VERSION "created by canmatrix"

NS_ :

BS_:

BU_: Pack01BMSLeader ExternalECU Pack02BMS Pack03BMS Pack04BMS Pack05BMS Pack06BMS Pack07BMS Pack08BMS Pack09BMS Pack10BMS Pack11BMS Pack12BMS Pack13BMS Pack14BMS Pack15BMS Pack16BMS

BO_ 2566834889 DM1: 550 Pack01BMSLeader

BO_ 2350631173 HVESSC1: 8 ExternalECU
 SG_ HVESS_High_Voltage_Bus_Connect_C : 0|2@1+ (1,0) [0|3] "" Pack01BMSLeader
 SG_ HVESS_Charging_Mode : 10|2@1+ (1,0) [0|3] "" Pack01BMSLeader

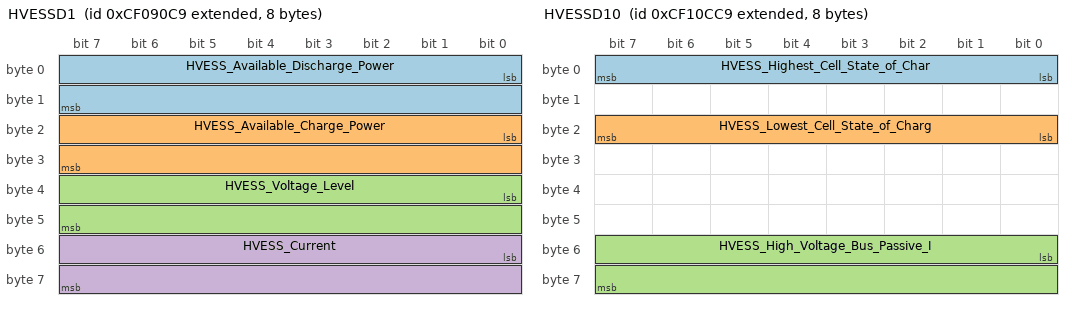
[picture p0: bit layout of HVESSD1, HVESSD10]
BO_ 2364575945 HVESSD1: 8 Pack01BMSLeader
 SG_ HVESS_Available_Discharge_Power : 0|16@1+ (0.05,0) [0|3276.75] "kW" Vector__XXX
 SG_ HVESS_Available_Charge_Power : 16|16@1+ (0.05,0) [0|3276.75] "kW" Vector__XXX
 SG_ HVESS_Voltage_Level : 32|16@1+ (0.05,0) [0|3276.75] "V" Vector__XXX
 SG_ HVESS_Current : 48|16@1+ (0.05,-1600) [-1600|1676.75] "A" Vector__XXX

BO_ 2364607689 HVESSD10: 8 Pack01BMSLeader
 SG_ HVESS_Highest_Cell_State_of_Char : 0|8@1+ (1,0) [0|255] "" Vector__XXX
 SG_ HVESS_Lowest_Cell_State_of_Charg : 16|8@1+ (1,0) [0|255] "" Vector__XXX
 SG_ HVESS_High_Voltage_Bus_Passive_I : 48|16@1+ (0.1,0) [0|6553.5] "ohm per V" Vector__XXX

BO_ 2365203657 HVESSD12: 8 Pack01BMSLeader
 SG_ HVESS_Estimated_Charge_Time_Rema : 24|16@1+ (0.1,0) [0|6553.5] "min" Vector__XXX

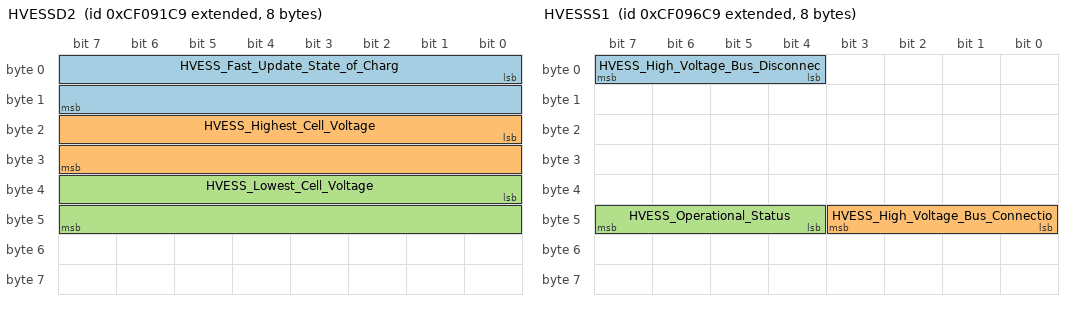
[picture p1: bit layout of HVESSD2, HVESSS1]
BO_ 2364576201 HVESSD2: 8 Pack01BMSLeader
 SG_ HVESS_Fast_Update_State_of_Charg : 0|16@1+ (0.0015625,0) [0|102.3984375] "%" Vector__XXX
 SG_ HVESS_Highest_Cell_Voltage : 16|16@1+ (0.001,0) [0|65.535] "V" Vector__XXX
 SG_ HVESS_Lowest_Cell_Voltage : 32|16@1+ (0.001,0) [0|65.535] "V" Vector__XXX

BO_ 2364576457 HVESSD3: 8 Pack01BMSLeader
 SG_ HVESS_Highest_Cell_Temperature : 0|16@1+ (0.03125,-273) [-273|1774.96875] "deg C" Vector__XXX
 SG_ HVESS_Lowest_Cell_Temperature : 16|16@1+ (0.03125,-273) [-273|1774.96875] "deg C" Vector__XXX

BO_ 2364576713 HVESSD4: 8 Pack01BMSLeader
 SG_ HVESS_Discharge_Capacity : 0|16@1+ (0.01,0) [0|655.35] "Ah" Vector__XXX
 SG_ HVESS_Charge_Capacity : 16|16@1+ (0.01,0) [0|655.35] "Ah" Vector__XXX

BO_ 2364576969 HVESSD5: 8 Pack01BMSLeader
 SG_ HVESS_Minimum_Cell_State_of_Char : 32|16@1+ (0.0015625,0) [0|102.3984375] "%" Vector__XXX
 SG_ HVESS_Maximum_Cell_State_of_Char : 48|16@1+ (0.0015625,0) [0|102.3984375] "%" Vector__XXX

BO_ 2364577225 HVESSD6: 8 Pack01BMSLeader
 SG_ HVESS_Bus_Voltage : 0|16@1+ (0.05,0) [0|3276.75] "V" Vector__XXX

BO_ 2364607177 HVESSD8: 8 Pack01BMSLeader
 SG_ HVESS_Highest_Cell_Voltage_Pack_ : 0|8@1+ (1,0) [0|255] "" Vector__XXX
 SG_ HVESS_Lowest_Cell_Voltage_Pack_N : 16|8@1+ (1,0) [0|255] "" Vector__XXX

BO_ 2364607433 HVESSD9: 8 Pack01BMSLeader
 SG_ HVESS_Highest_Cell_Temperature_P : 0|8@1+ (1,0) [0|255] "" Vector__XXX
 SG_ HVESS_Lowest_Cell_Temperature_Pa : 16|8@1+ (1,0) [0|255] "" Vector__XXX

BO_ 2633785033 HVESSHIST: 8 Pack01BMSLeader
 SG_ HVESS_State_of_Health : 0|8@1+ (0.4,0) [0|102] "%" Vector__XXX

BO_ 2364577481 HVESSS1: 8 Pack01BMSLeader
 SG_ HVESS_High_Voltage_Bus_Disconnec : 4|4@1+ (1,0) [0|15] "" Vector__XXX
 SG_ HVESS_High_Voltage_Bus_Connectio : 40|4@1+ (1,0) [0|15] "" Vector__XXX
 SG_ HVESS_Operational_Status : 44|4@1+ (1,0) [0|15] "" Vector__XXX

BO_ 2365522181 PropB_01: 8 ExternalECU
 SG_ External_Clear_DMs_Command : 0|2@1+ (1,0) [0|3] "" Vector__XXX
 SG_ Pack01_Disable_Command : 2|2@1+ (1,0) [0|3] "" Vector__XXX
 SG_ Pack02_Disable_Command : 4|2@1+ (1,0) [0|3] "" Vector__XXX
 SG_ Pack03_Disable_Command : 6|2@1+ (1,0) [0|3] "" Vector__XXX
 SG_ Pack04_Disable_Command : 8|2@1+ (1,0) [0|3] "" Vector__XXX
 SG_ Pack05_Disable_Command : 10|2@1+ (1,0) [0|3] "" Vector__XXX
 SG_ Pack06_Disable_Command : 12|2@1+ (1,0) [0|3] "" Vector__XXX
 SG_ Pack07_Disable_Command : 14|2@1+ (1,0) [0|3] "" Vector__XXX
 SG_ Pack08_Disable_Command : 16|2@1+ (1,0) [0|3] "" Vector__XXX
 SG_ Pack09_Disable_Command : 18|2@1+ (1,0) [0|3] "" Vector__XXX
 SG_ Pack10_Disable_Command : 20|2@1+ (1,0) [0|3] "" Vector__XXX
 SG_ Pack11_Disable_Command : 22|2@1+ (1,0) [0|3] "" Vector__XXX
 SG_ Pack12_Disable_Command : 24|2@1+ (1,0) [0|3] "" Vector__XXX
 SG_ Pack13_Disable_Command : 26|2@1+ (1,0) [0|3] "" Vector__XXX
 SG_ Pack14_Disable_Command : 28|2@1+ (1,0) [0|3] "" Vector__XXX
 SG_ Pack15_Disable_Command : 30|2@1+ (1,0) [0|3] "" Vector__XXX
 SG_ Pack16_Disable_Command : 32|2@1+ (1,0) [0|3] "" Vector__XXX

BO_ 2365522437 PropB_02: 8 ExternalECU
 SG_ Number_Packs_Configured : 0|8@1+ (1,0) [0|255] "" Vector__XXX

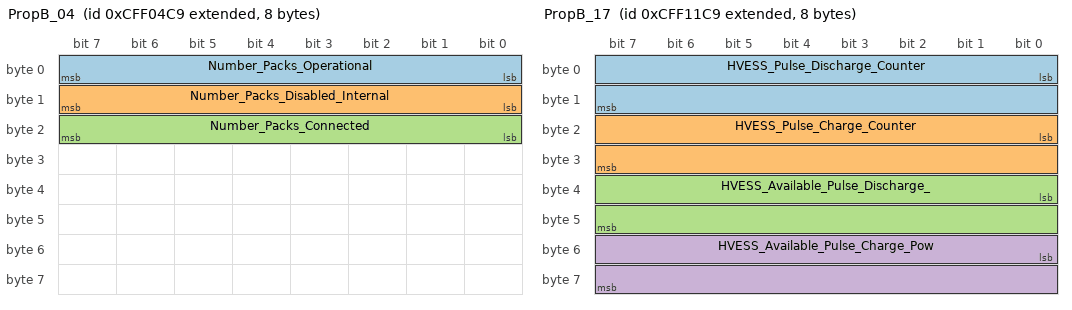
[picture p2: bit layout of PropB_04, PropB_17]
BO_ 2365523145 PropB_04: 8 Pack01BMSLeader
 SG_ Number_Packs_Operational : 0|8@1+ (1,0) [0|255] "" Vector__XXX
 SG_ Number_Packs_Disabled_Internal : 8|8@1+ (1,0) [0|255] "" Vector__XXX
 SG_ Number_Packs_Connected : 16|8@1+ (1,0) [0|255] "" Vector__XXX

BO_ 2365523401 PropB_05: 8 Pack01BMSLeader
 SG_ HVESS_Total_Lifetime_Energy_Inpu : 0|32@1+ (1,0) [0|4294967295] "kWh" Vector__XXX
 SG_ HVESS_Total_Lifetime_Energy_Outp : 32|32@1+ (1,0) [0|4294967295] "kWh" Vector__XXX

BO_ 2566852809 PropB_16: 227 Pack01BMSLeader
 SG_ Remaining_Capacity : 0|8@1+ (1,0) [0|255] "Ah" Vector__XXX
 SG_ Date_of_Manufacture_0 : 8|8@1+ (1,0) [0|255] "" Vector__XXX
 SG_ Date_of_Manufacture_1 : 16|8@1+ (1,0) [0|255] "" Vector__XXX
 SG_ Date_of_Manufacture_2 : 24|8@1+ (1,0) [0|255] "" Vector__XXX
 SG_ Date_of_Manufacture_3 : 32|8@1+ (1,0) [0|255] "" Vector__XXX
 SG_ Date_of_Manufacture_4 : 40|8@1+ (1,0) [0|255] "" Vector__XXX
 SG_ Date_of_Manufacture_5 : 48|8@1+ (1,0) [0|255] "" Vector__XXX
 SG_ Date_of_Manufacture_6 : 56|8@1+ (1,0) [0|255] "" Vector__XXX
 SG_ Date_of_Putting_Into_Service_0 : 64|8@1+ (1,0) [0|255] "" Vector__XXX
 SG_ Date_of_Putting_Into_Service_1 : 72|8@1+ (1,0) [0|255] "" Vector__XXX
 SG_ Date_of_Putting_Into_Service_2 : 80|8@1+ (1,0) [0|255] "" Vector__XXX
 SG_ Date_of_Putting_Into_Service_3 : 88|8@1+ (1,0) [0|255] "" Vector__XXX
 SG_ Date_of_Putting_Into_Service_4 : 96|8@1+ (1,0) [0|255] "" Vector__XXX
 SG_ Date_of_Putting_Into_Service_5 : 104|8@1+ (1,0) [0|255] "" Vector__XXX
 SG_ Date_of_Putting_Into_Service_6 : 112|8@1+ (1,0) [0|255] "" Vector__XXX
 SG_ Charge_Energy_Throughput : 120|24@1+ (1,0) [0|16777215] "kWh" Vector__XXX
 SG_ Discharge_Energy_Throughput : 144|24@1+ (1,0) [0|16777215] "kWh" Vector__XXX
 SG_ Total_Energy_Throughput : 168|24@1+ (1,0) [0|16777215] "kWh" Vector__XXX
 SG_ Charged_Capacity_Throughput : 192|24@1+ (1,0) [0|16777215] "Ah" Vector__XXX
 SG_ Discharged_Capacity_Throughput : 216|24@1+ (1,0) [0|16777215] "Ah" Vector__XXX
 SG_ Total_Capacity_Throughput : 240|24@1+ (1,0) [0|16777215] "Ah" Vector__XXX
 SG_ Number_of_Full_Equivalent_Charge0 : 264|16@1+ (1,0) [0|65535] "cycles" Vector__XXX
 SG_ Number_of_Full_Equivalent_Discha : 280|16@1+ (1,0) [0|65535] "cycles" Vector__XXX
 SG_ Number_of_Full_Equivalent_Charge1 : 296|16@1+ (1,0) [0|65535] "cycles" Vector__XXX
 SG_ Temperature_Histogram_0 : 312|32@1+ (1,0) [0|4294967295] "s" Vector__XXX
 SG_ Temperature_Histogram_1 : 344|32@1+ (1,0) [0|4294967295] "s" Vector__XXX
 SG_ Temperature_Histogram_2 : 376|32@1+ (1,0) [0|4294967295] "s" Vector__XXX
 SG_ Temperature_Histogram_3 : 408|32@1+ (1,0) [0|4294967295] "s" Vector__XXX
 SG_ Temperature_Histogram_4 : 440|32@1+ (1,0) [0|4294967295] "s" Vector__XXX
 SG_ Temperature_Histogram_5 : 472|32@1+ (1,0) [0|4294967295] "s" Vector__XXX
 SG_ Temperature_Histogram_6 : 504|32@1+ (1,0) [0|4294967295] "s" Vector__XXX
 SG_ Temperature_Histogram_7 : 536|32@1+ (1,0) [0|4294967295] "s" Vector__XXX
 SG_ Temperature_Histogram_8 : 568|32@1+ (1,0) [0|4294967295] "s" Vector__XXX
 SG_ Temperature_Histogram_9 : 600|32@1+ (1,0) [0|4294967295] "s" Vector__XXX
 SG_ Temperature_Histogram_10 : 632|32@1+ (1,0) [0|4294967295] "s" Vector__XXX
 SG_ Temperature_Histogram_11 : 664|32@1+ (1,0) [0|4294967295] "s" Vector__XXX
 SG_ Temperature_Histogram_12 : 696|32@1+ (1,0) [0|4294967295] "s" Vector__XXX
 SG_ Temperature_Histogram_13 : 728|32@1+ (1,0) [0|4294967295] "s" Vector__XXX
 SG_ Temperature_Histogram_14 : 760|32@1+ (1,0) [0|4294967295] "s" Vector__XXX
 SG_ Temperature_Histogram_15 : 792|32@1+ (1,0) [0|4294967295] "s" Vector__XXX
 SG_ Temperature_Histogram_16 : 824|32@1+ (1,0) [0|4294967295] "s" Vector__XXX
 SG_ Temperature_Histogram_17 : 856|32@1+ (1,0) [0|4294967295] "s" Vector__XXX
 SG_ Temperature_Histogram_18 : 888|32@1+ (1,0) [0|4294967295] "s" Vector__XXX
 SG_ Temperature_Histogram_19 : 920|32@1+ (1,0) [0|4294967295] "s" Vector__XXX
 SG_ Temperature_Histogram_20 : 952|32@1+ (1,0) [0|4294967295] "s" Vector__XXX
 SG_ Temperature_Histogram_21 : 984|32@1+ (1,0) [0|4294967295] "s" Vector__XXX
 SG_ Temperature_Histogram_22 : 1016|32@1+ (1,0) [0|4294967295] "s" Vector__XXX
 SG_ Temperature_Histogram_23 : 1048|32@1+ (1,0) [0|4294967295] "s" Vector__XXX
 SG_ Time_Spent_in_Extreme_Temperatur0 : 1080|32@1+ (1,0) [0|4294967295] "s" Vector__XXX
 SG_ Time_Spent_in_Extreme_Temperatur1 : 1112|32@1+ (1,0) [0|4294967295] "s" Vector__XXX
 SG_ Number_of_Deep_Discharge_Events : 1144|8@1+ (1,0) [0|255] "count" Vector__XXX
 SG_ Time_Spent_Charging_In_Extreme_T : 1152|8@1+ (1,0) [0|255] "s" Vector__XXX
 SG_ State_of_Charge : 1160|16@1+ (0.0015625,0) [0|102.3984375] "%" Vector__XXX
 SG_ State_of_Charge_Histogram_0 : 1176|32@1+ (1,0) [0|4294967295] "s" Vector__XXX
 SG_ State_of_Charge_Histogram_1 : 1208|32@1+ (1,0) [0|4294967295] "s" Vector__XXX
 SG_ State_of_Charge_Histogram_2 : 1240|32@1+ (1,0) [0|4294967295] "s" Vector__XXX
 SG_ State_of_Charge_Histogram_3 : 1272|32@1+ (1,0) [0|4294967295] "s" Vector__XXX
 SG_ State_of_Charge_Histogram_4 : 1304|32@1+ (1,0) [0|4294967295] "s" Vector__XXX
 SG_ State_of_Charge_Histogram_5 : 1336|32@1+ (1,0) [0|4294967295] "s" Vector__XXX
 SG_ State_of_Charge_Histogram_6 : 1368|32@1+ (1,0) [0|4294967295] "s" Vector__XXX
 SG_ State_of_Charge_Histogram_7 : 1400|32@1+ (1,0) [0|4294967295] "s" Vector__XXX
 SG_ State_of_Charge_Histogram_8 : 1432|32@1+ (1,0) [0|4294967295] "s" Vector__XXX
 SG_ State_of_Charge_Histogram_9 : 1464|32@1+ (1,0) [0|4294967295] "s" Vector__XXX
 SG_ State_of_Charge_Histogram_10 : 1496|32@1+ (1,0) [0|4294967295] "s" Vector__XXX
 SG_ State_of_Charge_Histogram_11 : 1528|32@1+ (1,0) [0|4294967295] "s" Vector__XXX
 SG_ State_of_Charge_Histogram_12 : 1560|32@1+ (1,0) [0|4294967295] "s" Vector__XXX
 SG_ State_of_Charge_Histogram_13 : 1592|32@1+ (1,0) [0|4294967295] "s" Vector__XXX
 SG_ State_of_Charge_Histogram_14 : 1624|32@1+ (1,0) [0|4294967295] "s" Vector__XXX
 SG_ State_of_Charge_Histogram_15 : 1656|32@1+ (1,0) [0|4294967295] "s" Vector__XXX
 SG_ State_of_Charge_Histogram_16 : 1688|32@1+ (1,0) [0|4294967295] "s" Vector__XXX
 SG_ State_of_Charge_Histogram_17 : 1720|32@1+ (1,0) [0|4294967295] "s" Vector__XXX
 SG_ State_of_Charge_Histogram_18 : 1752|32@1+ (1,0) [0|4294967295] "s" Vector__XXX
 SG_ State_of_Charge_Histogram_19 : 1784|32@1+ (1,0) [0|4294967295] "s" Vector__XXX

BO_ 2365526473 PropB_17: 8 Pack01BMSLeader
 SG_ HVESS_Pulse_Discharge_Counter : 0|16@1+ (0.02,0) [0|1310.7] "s" Vector__XXX
 SG_ HVESS_Pulse_Charge_Counter : 16|16@1+ (0.02,0) [0|1310.7] "s" Vector__XXX
 SG_ HVESS_Available_Pulse_Discharge_ : 32|16@1+ (0.05,0) [0|3276.75] "kW" Vector__XXX
 SG_ HVESS_Available_Pulse_Charge_Pow : 48|16@1+ (0.05,0) [0|3276.75] "kW" Vector__XXX

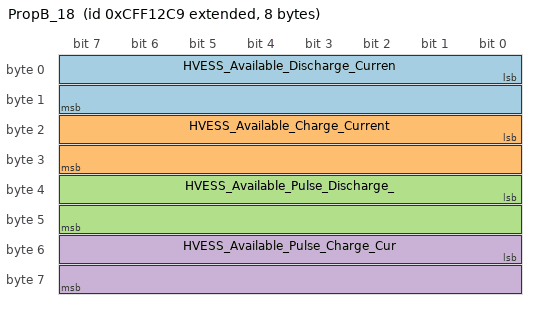
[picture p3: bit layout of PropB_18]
BO_ 2365526729 PropB_18: 8 Pack01BMSLeader
 SG_ HVESS_Available_Discharge_Curren : 0|16@1+ (0.125,-4000) [-4000|4191.875] "A" Vector__XXX
 SG_ HVESS_Available_Charge_Current : 16|16@1+ (0.125,-4000) [-4000|4191.875] "A" Vector__XXX
 SG_ HVESS_Available_Pulse_Discharge_ : 32|16@1+ (0.125,-4000) [-4000|4191.875] "A" Vector__XXX
 SG_ HVESS_Available_Pulse_Charge_Cur : 48|16@1+ (0.125,-4000) [-4000|4191.875] "A" Vector__XXX

BO_ 2365526985 PropB_19: 8 Pack01BMSLeader
 SG_ HVESS_Current_Extended_Range : 0|16@1+ (0.125,-4000) [-4000|4191.875] "A" Vector__XXX

BO_ 2566838985 SOFT: 222 Pack01BMSLeader

BO_ 2566768073 ECUID: 42 Pack01BMSLeader

BO_ 2566843337 CI: 39 Pack01BMSLeader

BO_ 2566834890 DM1_INTERPACK_Pack02BMS: 550 Pack02BMS

BO_ 2566834891 DM1_INTERPACK_Pack03BMS: 550 Pack03BMS

BO_ 2566834892 DM1_INTERPACK_Pack04BMS: 550 Pack04BMS

BO_ 2566834893 DM1_INTERPACK_Pack05BMS: 550 Pack05BMS

BO_ 2566834894 DM1_INTERPACK_Pack06BMS: 550 Pack06BMS

BO_ 2566834895 DM1_INTERPACK_Pack07BMS: 550 Pack07BMS

BO_ 2566834896 DM1_INTERPACK_Pack08BMS: 550 Pack08BMS

BO_ 2566834897 DM1_INTERPACK_Pack09BMS: 550 Pack09BMS

BO_ 2566834898 DM1_INTERPACK_Pack10BMS: 550 Pack10BMS

BO_ 2566834899 DM1_INTERPACK_Pack11BMS: 550 Pack11BMS

BO_ 2566834900 DM1_INTERPACK_Pack12BMS: 550 Pack12BMS

BO_ 2566834901 DM1_INTERPACK_Pack13BMS: 550 Pack13BMS

BO_ 2566834902 DM1_INTERPACK_Pack14BMS: 550 Pack14BMS

BO_ 2566834903 DM1_INTERPACK_Pack15BMS: 550 Pack15BMS

BO_ 2566834904 DM1_INTERPACK_Pack16BMS: 550 Pack16BMS

BO_ 2566852810 PropB_16_INTERPACK_Pack02BMS: 227 Pack02BMS
 SG_ Remaining_Capacity : 0|8@1+ (1,0) [0|255] "Ah" Vector__XXX
 SG_ Date_of_Manufacture_0 : 8|8@1+ (1,0) [0|255] "" Vector__XXX
 SG_ Date_of_Manufacture_1 : 16|8@1+ (1,0) [0|255] "" Vector__XXX
 SG_ Date_of_Manufacture_2 : 24|8@1+ (1,0) [0|255] "" Vector__XXX
 SG_ Date_of_Manufacture_3 : 32|8@1+ (1,0) [0|255] "" Vector__XXX
 SG_ Date_of_Manufacture_4 : 40|8@1+ (1,0) [0|255] "" Vector__XXX
 SG_ Date_of_Manufacture_5 : 48|8@1+ (1,0) [0|255] "" Vector__XXX
 SG_ Date_of_Manufacture_6 : 56|8@1+ (1,0) [0|255] "" Vector__XXX
 SG_ Date_of_Putting_Into_Service_0 : 64|8@1+ (1,0) [0|255] "" Vector__XXX
 SG_ Date_of_Putting_Into_Service_1 : 72|8@1+ (1,0) [0|255] "" Vector__XXX
 SG_ Date_of_Putting_Into_Service_2 : 80|8@1+ (1,0) [0|255] "" Vector__XXX
 SG_ Date_of_Putting_Into_Service_3 : 88|8@1+ (1,0) [0|255] "" Vector__XXX
 SG_ Date_of_Putting_Into_Service_4 : 96|8@1+ (1,0) [0|255] "" Vector__XXX
 SG_ Date_of_Putting_Into_Service_5 : 104|8@1+ (1,0) [0|255] "" Vector__XXX
 SG_ Date_of_Putting_Into_Service_6 : 112|8@1+ (1,0) [0|255] "" Vector__XXX
 SG_ Charge_Energy_Throughput : 120|24@1+ (1,0) [0|16777215] "kWh" Vector__XXX
 SG_ Discharge_Energy_Throughput : 144|24@1+ (1,0) [0|16777215] "kWh" Vector__XXX
 SG_ Total_Energy_Throughput : 168|24@1+ (1,0) [0|16777215] "kWh" Vector__XXX
 SG_ Charged_Capacity_Throughput : 192|24@1+ (1,0) [0|16777215] "Ah" Vector__XXX
 SG_ Discharged_Capacity_Throughput : 216|24@1+ (1,0) [0|16777215] "Ah" Vector__XXX
 SG_ Total_Capacity_Throughput : 240|24@1+ (1,0) [0|16777215] "Ah" Vector__XXX
 SG_ Number_of_Full_Equivalent_Charge0 : 264|16@1+ (1,0) [0|65535] "cycles" Vector__XXX
 SG_ Number_of_Full_Equivalent_Discha : 280|16@1+ (1,0) [0|65535] "cycles" Vector__XXX
 SG_ Number_of_Full_Equivalent_Charge1 : 296|16@1+ (1,0) [0|65535] "cycles" Vector__XXX
 SG_ Temperature_Histogram_0 : 312|32@1+ (1,0) [0|4294967295] "s" Vector__XXX
 SG_ Temperature_Histogram_1 : 344|32@1+ (1,0) [0|4294967295] "s" Vector__XXX
 SG_ Temperature_Histogram_2 : 376|32@1+ (1,0) [0|4294967295] "s" Vector__XXX
 SG_ Temperature_Histogram_3 : 408|32@1+ (1,0) [0|4294967295] "s" Vector__XXX
 SG_ Temperature_Histogram_4 : 440|32@1+ (1,0) [0|4294967295] "s" Vector__XXX
 SG_ Temperature_Histogram_5 : 472|32@1+ (1,0) [0|4294967295] "s" Vector__XXX
 SG_ Temperature_Histogram_6 : 504|32@1+ (1,0) [0|4294967295] "s" Vector__XXX
 SG_ Temperature_Histogram_7 : 536|32@1+ (1,0) [0|4294967295] "s" Vector__XXX
 SG_ Temperature_Histogram_8 : 568|32@1+ (1,0) [0|4294967295] "s" Vector__XXX
 SG_ Temperature_Histogram_9 : 600|32@1+ (1,0) [0|4294967295] "s" Vector__XXX
 SG_ Temperature_Histogram_10 : 632|32@1+ (1,0) [0|4294967295] "s" Vector__XXX
 SG_ Temperature_Histogram_11 : 664|32@1+ (1,0) [0|4294967295] "s" Vector__XXX
 SG_ Temperature_Histogram_12 : 696|32@1+ (1,0) [0|4294967295] "s" Vector__XXX
 SG_ Temperature_Histogram_13 : 728|32@1+ (1,0) [0|4294967295] "s" Vector__XXX
 SG_ Temperature_Histogram_14 : 760|32@1+ (1,0) [0|4294967295] "s" Vector__XXX
 SG_ Temperature_Histogram_15 : 792|32@1+ (1,0) [0|4294967295] "s" Vector__XXX
 SG_ Temperature_Histogram_16 : 824|32@1+ (1,0) [0|4294967295] "s" Vector__XXX
 SG_ Temperature_Histogram_17 : 856|32@1+ (1,0) [0|4294967295] "s" Vector__XXX
 SG_ Temperature_Histogram_18 : 888|32@1+ (1,0) [0|4294967295] "s" Vector__XXX
 SG_ Temperature_Histogram_19 : 920|32@1+ (1,0) [0|4294967295] "s" Vector__XXX
 SG_ Temperature_Histogram_20 : 952|32@1+ (1,0) [0|4294967295] "s" Vector__XXX
 SG_ Temperature_Histogram_21 : 984|32@1+ (1,0) [0|4294967295] "s" Vector__XXX
 SG_ Temperature_Histogram_22 : 1016|32@1+ (1,0) [0|4294967295] "s" Vector__XXX
 SG_ Temperature_Histogram_23 : 1048|32@1+ (1,0) [0|4294967295] "s" Vector__XXX
 SG_ Time_Spent_in_Extreme_Temperatur0 : 1080|32@1+ (1,0) [0|4294967295] "s" Vector__XXX
 SG_ Time_Spent_in_Extreme_Temperatur1 : 1112|32@1+ (1,0) [0|4294967295] "s" Vector__XXX
 SG_ Number_of_Deep_Discharge_Events : 1144|8@1+ (1,0) [0|255] "count" Vector__XXX
 SG_ Time_Spent_Charging_In_Extreme_T : 1152|8@1+ (1,0) [0|255] "s" Vector__XXX
 SG_ State_of_Charge : 1160|16@1+ (0.0015625,0) [0|102.3984375] "%" Vector__XXX
 SG_ State_of_Charge_Histogram_0 : 1176|32@1+ (1,0) [0|4294967295] "s" Vector__XXX
 SG_ State_of_Charge_Histogram_1 : 1208|32@1+ (1,0) [0|4294967295] "s" Vector__XXX
 SG_ State_of_Charge_Histogram_2 : 1240|32@1+ (1,0) [0|4294967295] "s" Vector__XXX
 SG_ State_of_Charge_Histogram_3 : 1272|32@1+ (1,0) [0|4294967295] "s" Vector__XXX
 SG_ State_of_Charge_Histogram_4 : 1304|32@1+ (1,0) [0|4294967295] "s" Vector__XXX
 SG_ State_of_Charge_Histogram_5 : 1336|32@1+ (1,0) [0|4294967295] "s" Vector__XXX
 SG_ State_of_Charge_Histogram_6 : 1368|32@1+ (1,0) [0|4294967295] "s" Vector__XXX
 SG_ State_of_Charge_Histogram_7 : 1400|32@1+ (1,0) [0|4294967295] "s" Vector__XXX
 SG_ State_of_Charge_Histogram_8 : 1432|32@1+ (1,0) [0|4294967295] "s" Vector__XXX
 SG_ State_of_Charge_Histogram_9 : 1464|32@1+ (1,0) [0|4294967295] "s" Vector__XXX
 SG_ State_of_Charge_Histogram_10 : 1496|32@1+ (1,0) [0|4294967295] "s" Vector__XXX
 SG_ State_of_Charge_Histogram_11 : 1528|32@1+ (1,0) [0|4294967295] "s" Vector__XXX
 SG_ State_of_Charge_Histogram_12 : 1560|32@1+ (1,0) [0|4294967295] "s" Vector__XXX
 SG_ State_of_Charge_Histogram_13 : 1592|32@1+ (1,0) [0|4294967295] "s" Vector__XXX
 SG_ State_of_Charge_Histogram_14 : 1624|32@1+ (1,0) [0|4294967295] "s" Vector__XXX
 SG_ State_of_Charge_Histogram_15 : 1656|32@1+ (1,0) [0|4294967295] "s" Vector__XXX
 SG_ State_of_Charge_Histogram_16 : 1688|32@1+ (1,0) [0|4294967295] "s" Vector__XXX
 SG_ State_of_Charge_Histogram_17 : 1720|32@1+ (1,0) [0|4294967295] "s" Vector__XXX
 SG_ State_of_Charge_Histogram_18 : 1752|32@1+ (1,0) [0|4294967295] "s" Vector__XXX
 SG_ State_of_Charge_Histogram_19 : 1784|32@1+ (1,0) [0|4294967295] "s" Vector__XXX

BO_ 2566852811 PropB_16_INTERPACK_Pack03BMS: 227 Pack03BMS
 SG_ Remaining_Capacity : 0|8@1+ (1,0) [0|255] "Ah" Vector__XXX
 SG_ Date_of_Manufacture_0 : 8|8@1+ (1,0) [0|255] "" Vector__XXX
 SG_ Date_of_Manufacture_1 : 16|8@1+ (1,0) [0|255] "" Vector__XXX
 SG_ Date_of_Manufacture_2 : 24|8@1+ (1,0) [0|255] "" Vector__XXX
 SG_ Date_of_Manufacture_3 : 32|8@1+ (1,0) [0|255] "" Vector__XXX
 SG_ Date_of_Manufacture_4 : 40|8@1+ (1,0) [0|255] "" Vector__XXX
 SG_ Date_of_Manufacture_5 : 48|8@1+ (1,0) [0|255] "" Vector__XXX
 SG_ Date_of_Manufacture_6 : 56|8@1+ (1,0) [0|255] "" Vector__XXX
 SG_ Date_of_Putting_Into_Service_0 : 64|8@1+ (1,0) [0|255] "" Vector__XXX
 SG_ Date_of_Putting_Into_Service_1 : 72|8@1+ (1,0) [0|255] "" Vector__XXX
 SG_ Date_of_Putting_Into_Service_2 : 80|8@1+ (1,0) [0|255] "" Vector__XXX
 SG_ Date_of_Putting_Into_Service_3 : 88|8@1+ (1,0) [0|255] "" Vector__XXX
 SG_ Date_of_Putting_Into_Service_4 : 96|8@1+ (1,0) [0|255] "" Vector__XXX
 SG_ Date_of_Putting_Into_Service_5 : 104|8@1+ (1,0) [0|255] "" Vector__XXX
 SG_ Date_of_Putting_Into_Service_6 : 112|8@1+ (1,0) [0|255] "" Vector__XXX
 SG_ Charge_Energy_Throughput : 120|24@1+ (1,0) [0|16777215] "kWh" Vector__XXX
 SG_ Discharge_Energy_Throughput : 144|24@1+ (1,0) [0|16777215] "kWh" Vector__XXX
 SG_ Total_Energy_Throughput : 168|24@1+ (1,0) [0|16777215] "kWh" Vector__XXX
 SG_ Charged_Capacity_Throughput : 192|24@1+ (1,0) [0|16777215] "Ah" Vector__XXX
 SG_ Discharged_Capacity_Throughput : 216|24@1+ (1,0) [0|16777215] "Ah" Vector__XXX
 SG_ Total_Capacity_Throughput : 240|24@1+ (1,0) [0|16777215] "Ah" Vector__XXX
 SG_ Number_of_Full_Equivalent_Charge0 : 264|16@1+ (1,0) [0|65535] "cycles" Vector__XXX
 SG_ Number_of_Full_Equivalent_Discha : 280|16@1+ (1,0) [0|65535] "cycles" Vector__XXX
 SG_ Number_of_Full_Equivalent_Charge1 : 296|16@1+ (1,0) [0|65535] "cycles" Vector__XXX
 SG_ Temperature_Histogram_0 : 312|32@1+ (1,0) [0|4294967295] "s" Vector__XXX
 SG_ Temperature_Histogram_1 : 344|32@1+ (1,0) [0|4294967295] "s" Vector__XXX
 SG_ Temperature_Histogram_2 : 376|32@1+ (1,0) [0|4294967295] "s" Vector__XXX
 SG_ Temperature_Histogram_3 : 408|32@1+ (1,0) [0|4294967295] "s" Vector__XXX
 SG_ Temperature_Histogram_4 : 440|32@1+ (1,0) [0|4294967295] "s" Vector__XXX
 SG_ Temperature_Histogram_5 : 472|32@1+ (1,0) [0|4294967295] "s" Vector__XXX
 SG_ Temperature_Histogram_6 : 504|32@1+ (1,0) [0|4294967295] "s" Vector__XXX
 SG_ Temperature_Histogram_7 : 536|32@1+ (1,0) [0|4294967295] "s" Vector__XXX
 SG_ Temperature_Histogram_8 : 568|32@1+ (1,0) [0|4294967295] "s" Vector__XXX
 SG_ Temperature_Histogram_9 : 600|32@1+ (1,0) [0|4294967295] "s" Vector__XXX
 SG_ Temperature_Histogram_10 : 632|32@1+ (1,0) [0|4294967295] "s" Vector__XXX
 SG_ Temperature_Histogram_11 : 664|32@1+ (1,0) [0|4294967295] "s" Vector__XXX
 SG_ Temperature_Histogram_12 : 696|32@1+ (1,0) [0|4294967295] "s" Vector__XXX
 SG_ Temperature_Histogram_13 : 728|32@1+ (1,0) [0|4294967295] "s" Vector__XXX
 SG_ Temperature_Histogram_14 : 760|32@1+ (1,0) [0|4294967295] "s" Vector__XXX
 SG_ Temperature_Histogram_15 : 792|32@1+ (1,0) [0|4294967295] "s" Vector__XXX
 SG_ Temperature_Histogram_16 : 824|32@1+ (1,0) [0|4294967295] "s" Vector__XXX
 SG_ Temperature_Histogram_17 : 856|32@1+ (1,0) [0|4294967295] "s" Vector__XXX
 SG_ Temperature_Histogram_18 : 888|32@1+ (1,0) [0|4294967295] "s" Vector__XXX
 SG_ Temperature_Histogram_19 : 920|32@1+ (1,0) [0|4294967295] "s" Vector__XXX
 SG_ Temperature_Histogram_20 : 952|32@1+ (1,0) [0|4294967295] "s" Vector__XXX
 SG_ Temperature_Histogram_21 : 984|32@1+ (1,0) [0|4294967295] "s" Vector__XXX
 SG_ Temperature_Histogram_22 : 1016|32@1+ (1,0) [0|4294967295] "s" Vector__XXX
 SG_ Temperature_Histogram_23 : 1048|32@1+ (1,0) [0|4294967295] "s" Vector__XXX
 SG_ Time_Spent_in_Extreme_Temperatur0 : 1080|32@1+ (1,0) [0|4294967295] "s" Vector__XXX
 SG_ Time_Spent_in_Extreme_Temperatur1 : 1112|32@1+ (1,0) [0|4294967295] "s" Vector__XXX
 SG_ Number_of_Deep_Discharge_Events : 1144|8@1+ (1,0) [0|255] "count" Vector__XXX
 SG_ Time_Spent_Charging_In_Extreme_T : 1152|8@1+ (1,0) [0|255] "s" Vector__XXX
 SG_ State_of_Charge : 1160|16@1+ (0.0015625,0) [0|102.3984375] "%" Vector__XXX
 SG_ State_of_Charge_Histogram_0 : 1176|32@1+ (1,0) [0|4294967295] "s" Vector__XXX
 SG_ State_of_Charge_Histogram_1 : 1208|32@1+ (1,0) [0|4294967295] "s" Vector__XXX
 SG_ State_of_Charge_Histogram_2 : 1240|32@1+ (1,0) [0|4294967295] "s" Vector__XXX
 SG_ State_of_Charge_Histogram_3 : 1272|32@1+ (1,0) [0|4294967295] "s" Vector__XXX
 SG_ State_of_Charge_Histogram_4 : 1304|32@1+ (1,0) [0|4294967295] "s" Vector__XXX
 SG_ State_of_Charge_Histogram_5 : 1336|32@1+ (1,0) [0|4294967295] "s" Vector__XXX
 SG_ State_of_Charge_Histogram_6 : 1368|32@1+ (1,0) [0|4294967295] "s" Vector__XXX
 SG_ State_of_Charge_Histogram_7 : 1400|32@1+ (1,0) [0|4294967295] "s" Vector__XXX
 SG_ State_of_Charge_Histogram_8 : 1432|32@1+ (1,0) [0|4294967295] "s" Vector__XXX
 SG_ State_of_Charge_Histogram_9 : 1464|32@1+ (1,0) [0|4294967295] "s" Vector__XXX
 SG_ State_of_Charge_Histogram_10 : 1496|32@1+ (1,0) [0|4294967295] "s" Vector__XXX
 SG_ State_of_Charge_Histogram_11 : 1528|32@1+ (1,0) [0|4294967295] "s" Vector__XXX
 SG_ State_of_Charge_Histogram_12 : 1560|32@1+ (1,0) [0|4294967295] "s" Vector__XXX
 SG_ State_of_Charge_Histogram_13 : 1592|32@1+ (1,0) [0|4294967295] "s" Vector__XXX
 SG_ State_of_Charge_Histogram_14 : 1624|32@1+ (1,0) [0|4294967295] "s" Vector__XXX
 SG_ State_of_Charge_Histogram_15 : 1656|32@1+ (1,0) [0|4294967295] "s" Vector__XXX
 SG_ State_of_Charge_Histogram_16 : 1688|32@1+ (1,0) [0|4294967295] "s" Vector__XXX
 SG_ State_of_Charge_Histogram_17 : 1720|32@1+ (1,0) [0|4294967295] "s" Vector__XXX
 SG_ State_of_Charge_Histogram_18 : 1752|32@1+ (1,0) [0|4294967295] "s" Vector__XXX
 SG_ State_of_Charge_Histogram_19 : 1784|32@1+ (1,0) [0|4294967295] "s" Vector__XXX

BO_ 2566852812 PropB_16_INTERPACK_Pack04BMS: 227 Pack04BMS
 SG_ Remaining_Capacity : 0|8@1+ (1,0) [0|255] "Ah" Vector__XXX
 SG_ Date_of_Manufacture_0 : 8|8@1+ (1,0) [0|255] "" Vector__XXX
 SG_ Date_of_Manufacture_1 : 16|8@1+ (1,0) [0|255] "" Vector__XXX
 SG_ Date_of_Manufacture_2 : 24|8@1+ (1,0) [0|255] "" Vector__XXX
 SG_ Date_of_Manufacture_3 : 32|8@1+ (1,0) [0|255] "" Vector__XXX
 SG_ Date_of_Manufacture_4 : 40|8@1+ (1,0) [0|255] "" Vector__XXX
 SG_ Date_of_Manufacture_5 : 48|8@1+ (1,0) [0|255] "" Vector__XXX
 SG_ Date_of_Manufacture_6 : 56|8@1+ (1,0) [0|255] "" Vector__XXX
 SG_ Date_of_Putting_Into_Service_0 : 64|8@1+ (1,0) [0|255] "" Vector__XXX
 SG_ Date_of_Putting_Into_Service_1 : 72|8@1+ (1,0) [0|255] "" Vector__XXX
 SG_ Date_of_Putting_Into_Service_2 : 80|8@1+ (1,0) [0|255] "" Vector__XXX
 SG_ Date_of_Putting_Into_Service_3 : 88|8@1+ (1,0) [0|255] "" Vector__XXX
 SG_ Date_of_Putting_Into_Service_4 : 96|8@1+ (1,0) [0|255] "" Vector__XXX
 SG_ Date_of_Putting_Into_Service_5 : 104|8@1+ (1,0) [0|255] "" Vector__XXX
 SG_ Date_of_Putting_Into_Service_6 : 112|8@1+ (1,0) [0|255] "" Vector__XXX
 SG_ Charge_Energy_Throughput : 120|24@1+ (1,0) [0|16777215] "kWh" Vector__XXX
 SG_ Discharge_Energy_Throughput : 144|24@1+ (1,0) [0|16777215] "kWh" Vector__XXX
 SG_ Total_Energy_Throughput : 168|24@1+ (1,0) [0|16777215] "kWh" Vector__XXX
 SG_ Charged_Capacity_Throughput : 192|24@1+ (1,0) [0|16777215] "Ah" Vector__XXX
 SG_ Discharged_Capacity_Throughput : 216|24@1+ (1,0) [0|16777215] "Ah" Vector__XXX
 SG_ Total_Capacity_Throughput : 240|24@1+ (1,0) [0|16777215] "Ah" Vector__XXX
 SG_ Number_of_Full_Equivalent_Charge0 : 264|16@1+ (1,0) [0|65535] "cycles" Vector__XXX
 SG_ Number_of_Full_Equivalent_Discha : 280|16@1+ (1,0) [0|65535] "cycles" Vector__XXX
 SG_ Number_of_Full_Equivalent_Charge1 : 296|16@1+ (1,0) [0|65535] "cycles" Vector__XXX
 SG_ Temperature_Histogram_0 : 312|32@1+ (1,0) [0|4294967295] "s" Vector__XXX
 SG_ Temperature_Histogram_1 : 344|32@1+ (1,0) [0|4294967295] "s" Vector__XXX
 SG_ Temperature_Histogram_2 : 376|32@1+ (1,0) [0|4294967295] "s" Vector__XXX
 SG_ Temperature_Histogram_3 : 408|32@1+ (1,0) [0|4294967295] "s" Vector__XXX
 SG_ Temperature_Histogram_4 : 440|32@1+ (1,0) [0|4294967295] "s" Vector__XXX
 SG_ Temperature_Histogram_5 : 472|32@1+ (1,0) [0|4294967295] "s" Vector__XXX
 SG_ Temperature_Histogram_6 : 504|32@1+ (1,0) [0|4294967295] "s" Vector__XXX
 SG_ Temperature_Histogram_7 : 536|32@1+ (1,0) [0|4294967295] "s" Vector__XXX
 SG_ Temperature_Histogram_8 : 568|32@1+ (1,0) [0|4294967295] "s" Vector__XXX
 SG_ Temperature_Histogram_9 : 600|32@1+ (1,0) [0|4294967295] "s" Vector__XXX
 SG_ Temperature_Histogram_10 : 632|32@1+ (1,0) [0|4294967295] "s" Vector__XXX
 SG_ Temperature_Histogram_11 : 664|32@1+ (1,0) [0|4294967295] "s" Vector__XXX
 SG_ Temperature_Histogram_12 : 696|32@1+ (1,0) [0|4294967295] "s" Vector__XXX
 SG_ Temperature_Histogram_13 : 728|32@1+ (1,0) [0|4294967295] "s" Vector__XXX
 SG_ Temperature_Histogram_14 : 760|32@1+ (1,0) [0|4294967295] "s" Vector__XXX
 SG_ Temperature_Histogram_15 : 792|32@1+ (1,0) [0|4294967295] "s" Vector__XXX
 SG_ Temperature_Histogram_16 : 824|32@1+ (1,0) [0|4294967295] "s" Vector__XXX
 SG_ Temperature_Histogram_17 : 856|32@1+ (1,0) [0|4294967295] "s" Vector__XXX
 SG_ Temperature_Histogram_18 : 888|32@1+ (1,0) [0|4294967295] "s" Vector__XXX
 SG_ Temperature_Histogram_19 : 920|32@1+ (1,0) [0|4294967295] "s" Vector__XXX
 SG_ Temperature_Histogram_20 : 952|32@1+ (1,0) [0|4294967295] "s" Vector__XXX
 SG_ Temperature_Histogram_21 : 984|32@1+ (1,0) [0|4294967295] "s" Vector__XXX
 SG_ Temperature_Histogram_22 : 1016|32@1+ (1,0) [0|4294967295] "s" Vector__XXX
 SG_ Temperature_Histogram_23 : 1048|32@1+ (1,0) [0|4294967295] "s" Vector__XXX
 SG_ Time_Spent_in_Extreme_Temperatur0 : 1080|32@1+ (1,0) [0|4294967295] "s" Vector__XXX
 SG_ Time_Spent_in_Extreme_Temperatur1 : 1112|32@1+ (1,0) [0|4294967295] "s" Vector__XXX
 SG_ Number_of_Deep_Discharge_Events : 1144|8@1+ (1,0) [0|255] "count" Vector__XXX
 SG_ Time_Spent_Charging_In_Extreme_T : 1152|8@1+ (1,0) [0|255] "s" Vector__XXX
 SG_ State_of_Charge : 1160|16@1+ (0.0015625,0) [0|102.3984375] "%" Vector__XXX
 SG_ State_of_Charge_Histogram_0 : 1176|32@1+ (1,0) [0|4294967295] "s" Vector__XXX
 SG_ State_of_Charge_Histogram_1 : 1208|32@1+ (1,0) [0|4294967295] "s" Vector__XXX
 SG_ State_of_Charge_Histogram_2 : 1240|32@1+ (1,0) [0|4294967295] "s" Vector__XXX
 SG_ State_of_Charge_Histogram_3 : 1272|32@1+ (1,0) [0|4294967295] "s" Vector__XXX
 SG_ State_of_Charge_Histogram_4 : 1304|32@1+ (1,0) [0|4294967295] "s" Vector__XXX
 SG_ State_of_Charge_Histogram_5 : 1336|32@1+ (1,0) [0|4294967295] "s" Vector__XXX
 SG_ State_of_Charge_Histogram_6 : 1368|32@1+ (1,0) [0|4294967295] "s" Vector__XXX
 SG_ State_of_Charge_Histogram_7 : 1400|32@1+ (1,0) [0|4294967295] "s" Vector__XXX
 SG_ State_of_Charge_Histogram_8 : 1432|32@1+ (1,0) [0|4294967295] "s" Vector__XXX
 SG_ State_of_Charge_Histogram_9 : 1464|32@1+ (1,0) [0|4294967295] "s" Vector__XXX
 SG_ State_of_Charge_Histogram_10 : 1496|32@1+ (1,0) [0|4294967295] "s" Vector__XXX
 SG_ State_of_Charge_Histogram_11 : 1528|32@1+ (1,0) [0|4294967295] "s" Vector__XXX
 SG_ State_of_Charge_Histogram_12 : 1560|32@1+ (1,0) [0|4294967295] "s" Vector__XXX
 SG_ State_of_Charge_Histogram_13 : 1592|32@1+ (1,0) [0|4294967295] "s" Vector__XXX
 SG_ State_of_Charge_Histogram_14 : 1624|32@1+ (1,0) [0|4294967295] "s" Vector__XXX
 SG_ State_of_Charge_Histogram_15 : 1656|32@1+ (1,0) [0|4294967295] "s" Vector__XXX
 SG_ State_of_Charge_Histogram_16 : 1688|32@1+ (1,0) [0|4294967295] "s" Vector__XXX
 SG_ State_of_Charge_Histogram_17 : 1720|32@1+ (1,0) [0|4294967295] "s" Vector__XXX
 SG_ State_of_Charge_Histogram_18 : 1752|32@1+ (1,0) [0|4294967295] "s" Vector__XXX
 SG_ State_of_Charge_Histogram_19 : 1784|32@1+ (1,0) [0|4294967295] "s" Vector__XXX

BO_ 2566852813 PropB_16_INTERPACK_Pack05BMS: 227 Pack05BMS
 SG_ Remaining_Capacity : 0|8@1+ (1,0) [0|255] "Ah" Vector__XXX
 SG_ Date_of_Manufacture_0 : 8|8@1+ (1,0) [0|255] "" Vector__XXX
 SG_ Date_of_Manufacture_1 : 16|8@1+ (1,0) [0|255] "" Vector__XXX
 SG_ Date_of_Manufacture_2 : 24|8@1+ (1,0) [0|255] "" Vector__XXX
 SG_ Date_of_Manufacture_3 : 32|8@1+ (1,0) [0|255] "" Vector__XXX
 SG_ Date_of_Manufacture_4 : 40|8@1+ (1,0) [0|255] "" Vector__XXX
 SG_ Date_of_Manufacture_5 : 48|8@1+ (1,0) [0|255] "" Vector__XXX
 SG_ Date_of_Manufacture_6 : 56|8@1+ (1,0) [0|255] "" Vector__XXX
 SG_ Date_of_Putting_Into_Service_0 : 64|8@1+ (1,0) [0|255] "" Vector__XXX
 SG_ Date_of_Putting_Into_Service_1 : 72|8@1+ (1,0) [0|255] "" Vector__XXX
 SG_ Date_of_Putting_Into_Service_2 : 80|8@1+ (1,0) [0|255] "" Vector__XXX
 SG_ Date_of_Putting_Into_Service_3 : 88|8@1+ (1,0) [0|255] "" Vector__XXX
 SG_ Date_of_Putting_Into_Service_4 : 96|8@1+ (1,0) [0|255] "" Vector__XXX
 SG_ Date_of_Putting_Into_Service_5 : 104|8@1+ (1,0) [0|255] "" Vector__XXX
 SG_ Date_of_Putting_Into_Service_6 : 112|8@1+ (1,0) [0|255] "" Vector__XXX
 SG_ Charge_Energy_Throughput : 120|24@1+ (1,0) [0|16777215] "kWh" Vector__XXX
 SG_ Discharge_Energy_Throughput : 144|24@1+ (1,0) [0|16777215] "kWh" Vector__XXX
 SG_ Total_Energy_Throughput : 168|24@1+ (1,0) [0|16777215] "kWh" Vector__XXX
 SG_ Charged_Capacity_Throughput : 192|24@1+ (1,0) [0|16777215] "Ah" Vector__XXX
 SG_ Discharged_Capacity_Throughput : 216|24@1+ (1,0) [0|16777215] "Ah" Vector__XXX
 SG_ Total_Capacity_Throughput : 240|24@1+ (1,0) [0|16777215] "Ah" Vector__XXX
 SG_ Number_of_Full_Equivalent_Charge0 : 264|16@1+ (1,0) [0|65535] "cycles" Vector__XXX
 SG_ Number_of_Full_Equivalent_Discha : 280|16@1+ (1,0) [0|65535] "cycles" Vector__XXX
 SG_ Number_of_Full_Equivalent_Charge1 : 296|16@1+ (1,0) [0|65535] "cycles" Vector__XXX
 SG_ Temperature_Histogram_0 : 312|32@1+ (1,0) [0|4294967295] "s" Vector__XXX
 SG_ Temperature_Histogram_1 : 344|32@1+ (1,0) [0|4294967295] "s" Vector__XXX
 SG_ Temperature_Histogram_2 : 376|32@1+ (1,0) [0|4294967295] "s" Vector__XXX
 SG_ Temperature_Histogram_3 : 408|32@1+ (1,0) [0|4294967295] "s" Vector__XXX
 SG_ Temperature_Histogram_4 : 440|32@1+ (1,0) [0|4294967295] "s" Vector__XXX
 SG_ Temperature_Histogram_5 : 472|32@1+ (1,0) [0|4294967295] "s" Vector__XXX
 SG_ Temperature_Histogram_6 : 504|32@1+ (1,0) [0|4294967295] "s" Vector__XXX
 SG_ Temperature_Histogram_7 : 536|32@1+ (1,0) [0|4294967295] "s" Vector__XXX
 SG_ Temperature_Histogram_8 : 568|32@1+ (1,0) [0|4294967295] "s" Vector__XXX
 SG_ Temperature_Histogram_9 : 600|32@1+ (1,0) [0|4294967295] "s" Vector__XXX
 SG_ Temperature_Histogram_10 : 632|32@1+ (1,0) [0|4294967295] "s" Vector__XXX
 SG_ Temperature_Histogram_11 : 664|32@1+ (1,0) [0|4294967295] "s" Vector__XXX
 SG_ Temperature_Histogram_12 : 696|32@1+ (1,0) [0|4294967295] "s" Vector__XXX
 SG_ Temperature_Histogram_13 : 728|32@1+ (1,0) [0|4294967295] "s" Vector__XXX
 SG_ Temperature_Histogram_14 : 760|32@1+ (1,0) [0|4294967295] "s" Vector__XXX
 SG_ Temperature_Histogram_15 : 792|32@1+ (1,0) [0|4294967295] "s" Vector__XXX
 SG_ Temperature_Histogram_16 : 824|32@1+ (1,0) [0|4294967295] "s" Vector__XXX
 SG_ Temperature_Histogram_17 : 856|32@1+ (1,0) [0|4294967295] "s" Vector__XXX
 SG_ Temperature_Histogram_18 : 888|32@1+ (1,0) [0|4294967295] "s" Vector__XXX
 SG_ Temperature_Histogram_19 : 920|32@1+ (1,0) [0|4294967295] "s" Vector__XXX
 SG_ Temperature_Histogram_20 : 952|32@1+ (1,0) [0|4294967295] "s" Vector__XXX
 SG_ Temperature_Histogram_21 : 984|32@1+ (1,0) [0|4294967295] "s" Vector__XXX
 SG_ Temperature_Histogram_22 : 1016|32@1+ (1,0) [0|4294967295] "s" Vector__XXX
 SG_ Temperature_Histogram_23 : 1048|32@1+ (1,0) [0|4294967295] "s" Vector__XXX
 SG_ Time_Spent_in_Extreme_Temperatur0 : 1080|32@1+ (1,0) [0|4294967295] "s" Vector__XXX
 SG_ Time_Spent_in_Extreme_Temperatur1 : 1112|32@1+ (1,0) [0|4294967295] "s" Vector__XXX
 SG_ Number_of_Deep_Discharge_Events : 1144|8@1+ (1,0) [0|255] "count" Vector__XXX
 SG_ Time_Spent_Charging_In_Extreme_T : 1152|8@1+ (1,0) [0|255] "s" Vector__XXX
 SG_ State_of_Charge : 1160|16@1+ (0.0015625,0) [0|102.3984375] "%" Vector__XXX
 SG_ State_of_Charge_Histogram_0 : 1176|32@1+ (1,0) [0|4294967295] "s" Vector__XXX
 SG_ State_of_Charge_Histogram_1 : 1208|32@1+ (1,0) [0|4294967295] "s" Vector__XXX
 SG_ State_of_Charge_Histogram_2 : 1240|32@1+ (1,0) [0|4294967295] "s" Vector__XXX
 SG_ State_of_Charge_Histogram_3 : 1272|32@1+ (1,0) [0|4294967295] "s" Vector__XXX
 SG_ State_of_Charge_Histogram_4 : 1304|32@1+ (1,0) [0|4294967295] "s" Vector__XXX
 SG_ State_of_Charge_Histogram_5 : 1336|32@1+ (1,0) [0|4294967295] "s" Vector__XXX
 SG_ State_of_Charge_Histogram_6 : 1368|32@1+ (1,0) [0|4294967295] "s" Vector__XXX
 SG_ State_of_Charge_Histogram_7 : 1400|32@1+ (1,0) [0|4294967295] "s" Vector__XXX
 SG_ State_of_Charge_Histogram_8 : 1432|32@1+ (1,0) [0|4294967295] "s" Vector__XXX
 SG_ State_of_Charge_Histogram_9 : 1464|32@1+ (1,0) [0|4294967295] "s" Vector__XXX
 SG_ State_of_Charge_Histogram_10 : 1496|32@1+ (1,0) [0|4294967295] "s" Vector__XXX
 SG_ State_of_Charge_Histogram_11 : 1528|32@1+ (1,0) [0|4294967295] "s" Vector__XXX
 SG_ State_of_Charge_Histogram_12 : 1560|32@1+ (1,0) [0|4294967295] "s" Vector__XXX
 SG_ State_of_Charge_Histogram_13 : 1592|32@1+ (1,0) [0|4294967295] "s" Vector__XXX
 SG_ State_of_Charge_Histogram_14 : 1624|32@1+ (1,0) [0|4294967295] "s" Vector__XXX
 SG_ State_of_Charge_Histogram_15 : 1656|32@1+ (1,0) [0|4294967295] "s" Vector__XXX
 SG_ State_of_Charge_Histogram_16 : 1688|32@1+ (1,0) [0|4294967295] "s" Vector__XXX
 SG_ State_of_Charge_Histogram_17 : 1720|32@1+ (1,0) [0|4294967295] "s" Vector__XXX
 SG_ State_of_Charge_Histogram_18 : 1752|32@1+ (1,0) [0|4294967295] "s" Vector__XXX
 SG_ State_of_Charge_Histogram_19 : 1784|32@1+ (1,0) [0|4294967295] "s" Vector__XXX

BO_ 2566852814 PropB_16_INTERPACK_Pack06BMS: 227 Pack06BMS
 SG_ Remaining_Capacity : 0|8@1+ (1,0) [0|255] "Ah" Vector__XXX
 SG_ Date_of_Manufacture_0 : 8|8@1+ (1,0) [0|255] "" Vector__XXX
 SG_ Date_of_Manufacture_1 : 16|8@1+ (1,0) [0|255] "" Vector__XXX
 SG_ Date_of_Manufacture_2 : 24|8@1+ (1,0) [0|255] "" Vector__XXX
 SG_ Date_of_Manufacture_3 : 32|8@1+ (1,0) [0|255] "" Vector__XXX
 SG_ Date_of_Manufacture_4 : 40|8@1+ (1,0) [0|255] "" Vector__XXX
 SG_ Date_of_Manufacture_5 : 48|8@1+ (1,0) [0|255] "" Vector__XXX
 SG_ Date_of_Manufacture_6 : 56|8@1+ (1,0) [0|255] "" Vector__XXX
 SG_ Date_of_Putting_Into_Service_0 : 64|8@1+ (1,0) [0|255] "" Vector__XXX
 SG_ Date_of_Putting_Into_Service_1 : 72|8@1+ (1,0) [0|255] "" Vector__XXX
 SG_ Date_of_Putting_Into_Service_2 : 80|8@1+ (1,0) [0|255] "" Vector__XXX
 SG_ Date_of_Putting_Into_Service_3 : 88|8@1+ (1,0) [0|255] "" Vector__XXX
 SG_ Date_of_Putting_Into_Service_4 : 96|8@1+ (1,0) [0|255] "" Vector__XXX
 SG_ Date_of_Putting_Into_Service_5 : 104|8@1+ (1,0) [0|255] "" Vector__XXX
 SG_ Date_of_Putting_Into_Service_6 : 112|8@1+ (1,0) [0|255] "" Vector__XXX
 SG_ Charge_Energy_Throughput : 120|24@1+ (1,0) [0|16777215] "kWh" Vector__XXX
 SG_ Discharge_Energy_Throughput : 144|24@1+ (1,0) [0|16777215] "kWh" Vector__XXX
 SG_ Total_Energy_Throughput : 168|24@1+ (1,0) [0|16777215] "kWh" Vector__XXX
 SG_ Charged_Capacity_Throughput : 192|24@1+ (1,0) [0|16777215] "Ah" Vector__XXX
 SG_ Discharged_Capacity_Throughput : 216|24@1+ (1,0) [0|16777215] "Ah" Vector__XXX
 SG_ Total_Capacity_Throughput : 240|24@1+ (1,0) [0|16777215] "Ah" Vector__XXX
 SG_ Number_of_Full_Equivalent_Charge0 : 264|16@1+ (1,0) [0|65535] "cycles" Vector__XXX
 SG_ Number_of_Full_Equivalent_Discha : 280|16@1+ (1,0) [0|65535] "cycles" Vector__XXX
 SG_ Number_of_Full_Equivalent_Charge1 : 296|16@1+ (1,0) [0|65535] "cycles" Vector__XXX
 SG_ Temperature_Histogram_0 : 312|32@1+ (1,0) [0|4294967295] "s" Vector__XXX
 SG_ Temperature_Histogram_1 : 344|32@1+ (1,0) [0|4294967295] "s" Vector__XXX
 SG_ Temperature_Histogram_2 : 376|32@1+ (1,0) [0|4294967295] "s" Vector__XXX
 SG_ Temperature_Histogram_3 : 408|32@1+ (1,0) [0|4294967295] "s" Vector__XXX
 SG_ Temperature_Histogram_4 : 440|32@1+ (1,0) [0|4294967295] "s" Vector__XXX
 SG_ Temperature_Histogram_5 : 472|32@1+ (1,0) [0|4294967295] "s" Vector__XXX
 SG_ Temperature_Histogram_6 : 504|32@1+ (1,0) [0|4294967295] "s" Vector__XXX
 SG_ Temperature_Histogram_7 : 536|32@1+ (1,0) [0|4294967295] "s" Vector__XXX
 SG_ Temperature_Histogram_8 : 568|32@1+ (1,0) [0|4294967295] "s" Vector__XXX
 SG_ Temperature_Histogram_9 : 600|32@1+ (1,0) [0|4294967295] "s" Vector__XXX
 SG_ Temperature_Histogram_10 : 632|32@1+ (1,0) [0|4294967295] "s" Vector__XXX
 SG_ Temperature_Histogram_11 : 664|32@1+ (1,0) [0|4294967295] "s" Vector__XXX
 SG_ Temperature_Histogram_12 : 696|32@1+ (1,0) [0|4294967295] "s" Vector__XXX
 SG_ Temperature_Histogram_13 : 728|32@1+ (1,0) [0|4294967295] "s" Vector__XXX
 SG_ Temperature_Histogram_14 : 760|32@1+ (1,0) [0|4294967295] "s" Vector__XXX
 SG_ Temperature_Histogram_15 : 792|32@1+ (1,0) [0|4294967295] "s" Vector__XXX
 SG_ Temperature_Histogram_16 : 824|32@1+ (1,0) [0|4294967295] "s" Vector__XXX
 SG_ Temperature_Histogram_17 : 856|32@1+ (1,0) [0|4294967295] "s" Vector__XXX
 SG_ Temperature_Histogram_18 : 888|32@1+ (1,0) [0|4294967295] "s" Vector__XXX
 SG_ Temperature_Histogram_19 : 920|32@1+ (1,0) [0|4294967295] "s" Vector__XXX
 SG_ Temperature_Histogram_20 : 952|32@1+ (1,0) [0|4294967295] "s" Vector__XXX
 SG_ Temperature_Histogram_21 : 984|32@1+ (1,0) [0|4294967295] "s" Vector__XXX
 SG_ Temperature_Histogram_22 : 1016|32@1+ (1,0) [0|4294967295] "s" Vector__XXX
 SG_ Temperature_Histogram_23 : 1048|32@1+ (1,0) [0|4294967295] "s" Vector__XXX
 SG_ Time_Spent_in_Extreme_Temperatur0 : 1080|32@1+ (1,0) [0|4294967295] "s" Vector__XXX
 SG_ Time_Spent_in_Extreme_Temperatur1 : 1112|32@1+ (1,0) [0|4294967295] "s" Vector__XXX
 SG_ Number_of_Deep_Discharge_Events : 1144|8@1+ (1,0) [0|255] "count" Vector__XXX
 SG_ Time_Spent_Charging_In_Extreme_T : 1152|8@1+ (1,0) [0|255] "s" Vector__XXX
 SG_ State_of_Charge : 1160|16@1+ (0.0015625,0) [0|102.3984375] "%" Vector__XXX
 SG_ State_of_Charge_Histogram_0 : 1176|32@1+ (1,0) [0|4294967295] "s" Vector__XXX
 SG_ State_of_Charge_Histogram_1 : 1208|32@1+ (1,0) [0|4294967295] "s" Vector__XXX
 SG_ State_of_Charge_Histogram_2 : 1240|32@1+ (1,0) [0|4294967295] "s" Vector__XXX
 SG_ State_of_Charge_Histogram_3 : 1272|32@1+ (1,0) [0|4294967295] "s" Vector__XXX
 SG_ State_of_Charge_Histogram_4 : 1304|32@1+ (1,0) [0|4294967295] "s" Vector__XXX
 SG_ State_of_Charge_Histogram_5 : 1336|32@1+ (1,0) [0|4294967295] "s" Vector__XXX
 SG_ State_of_Charge_Histogram_6 : 1368|32@1+ (1,0) [0|4294967295] "s" Vector__XXX
 SG_ State_of_Charge_Histogram_7 : 1400|32@1+ (1,0) [0|4294967295] "s" Vector__XXX
 SG_ State_of_Charge_Histogram_8 : 1432|32@1+ (1,0) [0|4294967295] "s" Vector__XXX
 SG_ State_of_Charge_Histogram_9 : 1464|32@1+ (1,0) [0|4294967295] "s" Vector__XXX
 SG_ State_of_Charge_Histogram_10 : 1496|32@1+ (1,0) [0|4294967295] "s" Vector__XXX
 SG_ State_of_Charge_Histogram_11 : 1528|32@1+ (1,0) [0|4294967295] "s" Vector__XXX
 SG_ State_of_Charge_Histogram_12 : 1560|32@1+ (1,0) [0|4294967295] "s" Vector__XXX
 SG_ State_of_Charge_Histogram_13 : 1592|32@1+ (1,0) [0|4294967295] "s" Vector__XXX
 SG_ State_of_Charge_Histogram_14 : 1624|32@1+ (1,0) [0|4294967295] "s" Vector__XXX
 SG_ State_of_Charge_Histogram_15 : 1656|32@1+ (1,0) [0|4294967295] "s" Vector__XXX
 SG_ State_of_Charge_Histogram_16 : 1688|32@1+ (1,0) [0|4294967295] "s" Vector__XXX
 SG_ State_of_Charge_Histogram_17 : 1720|32@1+ (1,0) [0|4294967295] "s" Vector__XXX
 SG_ State_of_Charge_Histogram_18 : 1752|32@1+ (1,0) [0|4294967295] "s" Vector__XXX
 SG_ State_of_Charge_Histogram_19 : 1784|32@1+ (1,0) [0|4294967295] "s" Vector__XXX

BO_ 2566852815 PropB_16_INTERPACK_Pack07BMS: 227 Pack07BMS
 SG_ Remaining_Capacity : 0|8@1+ (1,0) [0|255] "Ah" Vector__XXX
 SG_ Date_of_Manufacture_0 : 8|8@1+ (1,0) [0|255] "" Vector__XXX
 SG_ Date_of_Manufacture_1 : 16|8@1+ (1,0) [0|255] "" Vector__XXX
 SG_ Date_of_Manufacture_2 : 24|8@1+ (1,0) [0|255] "" Vector__XXX
 SG_ Date_of_Manufacture_3 : 32|8@1+ (1,0) [0|255] "" Vector__XXX
 SG_ Date_of_Manufacture_4 : 40|8@1+ (1,0) [0|255] "" Vector__XXX
 SG_ Date_of_Manufacture_5 : 48|8@1+ (1,0) [0|255] "" Vector__XXX
 SG_ Date_of_Manufacture_6 : 56|8@1+ (1,0) [0|255] "" Vector__XXX
 SG_ Date_of_Putting_Into_Service_0 : 64|8@1+ (1,0) [0|255] "" Vector__XXX
 SG_ Date_of_Putting_Into_Service_1 : 72|8@1+ (1,0) [0|255] "" Vector__XXX
 SG_ Date_of_Putting_Into_Service_2 : 80|8@1+ (1,0) [0|255] "" Vector__XXX
 SG_ Date_of_Putting_Into_Service_3 : 88|8@1+ (1,0) [0|255] "" Vector__XXX
 SG_ Date_of_Putting_Into_Service_4 : 96|8@1+ (1,0) [0|255] "" Vector__XXX
 SG_ Date_of_Putting_Into_Service_5 : 104|8@1+ (1,0) [0|255] "" Vector__XXX
 SG_ Date_of_Putting_Into_Service_6 : 112|8@1+ (1,0) [0|255] "" Vector__XXX
 SG_ Charge_Energy_Throughput : 120|24@1+ (1,0) [0|16777215] "kWh" Vector__XXX
 SG_ Discharge_Energy_Throughput : 144|24@1+ (1,0) [0|16777215] "kWh" Vector__XXX
 SG_ Total_Energy_Throughput : 168|24@1+ (1,0) [0|16777215] "kWh" Vector__XXX
 SG_ Charged_Capacity_Throughput : 192|24@1+ (1,0) [0|16777215] "Ah" Vector__XXX
 SG_ Discharged_Capacity_Throughput : 216|24@1+ (1,0) [0|16777215] "Ah" Vector__XXX
 SG_ Total_Capacity_Throughput : 240|24@1+ (1,0) [0|16777215] "Ah" Vector__XXX
 SG_ Number_of_Full_Equivalent_Charge0 : 264|16@1+ (1,0) [0|65535] "cycles" Vector__XXX
 SG_ Number_of_Full_Equivalent_Discha : 280|16@1+ (1,0) [0|65535] "cycles" Vector__XXX
 SG_ Number_of_Full_Equivalent_Charge1 : 296|16@1+ (1,0) [0|65535] "cycles" Vector__XXX
 SG_ Temperature_Histogram_0 : 312|32@1+ (1,0) [0|4294967295] "s" Vector__XXX
 SG_ Temperature_Histogram_1 : 344|32@1+ (1,0) [0|4294967295] "s" Vector__XXX
 SG_ Temperature_Histogram_2 : 376|32@1+ (1,0) [0|4294967295] "s" Vector__XXX
 SG_ Temperature_Histogram_3 : 408|32@1+ (1,0) [0|4294967295] "s" Vector__XXX
 SG_ Temperature_Histogram_4 : 440|32@1+ (1,0) [0|4294967295] "s" Vector__XXX
 SG_ Temperature_Histogram_5 : 472|32@1+ (1,0) [0|4294967295] "s" Vector__XXX
 SG_ Temperature_Histogram_6 : 504|32@1+ (1,0) [0|4294967295] "s" Vector__XXX
 SG_ Temperature_Histogram_7 : 536|32@1+ (1,0) [0|4294967295] "s" Vector__XXX
 SG_ Temperature_Histogram_8 : 568|32@1+ (1,0) [0|4294967295] "s" Vector__XXX
 SG_ Temperature_Histogram_9 : 600|32@1+ (1,0) [0|4294967295] "s" Vector__XXX
 SG_ Temperature_Histogram_10 : 632|32@1+ (1,0) [0|4294967295] "s" Vector__XXX
 SG_ Temperature_Histogram_11 : 664|32@1+ (1,0) [0|4294967295] "s" Vector__XXX
 SG_ Temperature_Histogram_12 : 696|32@1+ (1,0) [0|4294967295] "s" Vector__XXX
 SG_ Temperature_Histogram_13 : 728|32@1+ (1,0) [0|4294967295] "s" Vector__XXX
 SG_ Temperature_Histogram_14 : 760|32@1+ (1,0) [0|4294967295] "s" Vector__XXX
 SG_ Temperature_Histogram_15 : 792|32@1+ (1,0) [0|4294967295] "s" Vector__XXX
 SG_ Temperature_Histogram_16 : 824|32@1+ (1,0) [0|4294967295] "s" Vector__XXX
 SG_ Temperature_Histogram_17 : 856|32@1+ (1,0) [0|4294967295] "s" Vector__XXX
 SG_ Temperature_Histogram_18 : 888|32@1+ (1,0) [0|4294967295] "s" Vector__XXX
 SG_ Temperature_Histogram_19 : 920|32@1+ (1,0) [0|4294967295] "s" Vector__XXX
 SG_ Temperature_Histogram_20 : 952|32@1+ (1,0) [0|4294967295] "s" Vector__XXX
 SG_ Temperature_Histogram_21 : 984|32@1+ (1,0) [0|4294967295] "s" Vector__XXX
 SG_ Temperature_Histogram_22 : 1016|32@1+ (1,0) [0|4294967295] "s" Vector__XXX
 SG_ Temperature_Histogram_23 : 1048|32@1+ (1,0) [0|4294967295] "s" Vector__XXX
 SG_ Time_Spent_in_Extreme_Temperatur0 : 1080|32@1+ (1,0) [0|4294967295] "s" Vector__XXX
 SG_ Time_Spent_in_Extreme_Temperatur1 : 1112|32@1+ (1,0) [0|4294967295] "s" Vector__XXX
 SG_ Number_of_Deep_Discharge_Events : 1144|8@1+ (1,0) [0|255] "count" Vector__XXX
 SG_ Time_Spent_Charging_In_Extreme_T : 1152|8@1+ (1,0) [0|255] "s" Vector__XXX
 SG_ State_of_Charge : 1160|16@1+ (0.0015625,0) [0|102.3984375] "%" Vector__XXX
 SG_ State_of_Charge_Histogram_0 : 1176|32@1+ (1,0) [0|4294967295] "s" Vector__XXX
 SG_ State_of_Charge_Histogram_1 : 1208|32@1+ (1,0) [0|4294967295] "s" Vector__XXX
 SG_ State_of_Charge_Histogram_2 : 1240|32@1+ (1,0) [0|4294967295] "s" Vector__XXX
 SG_ State_of_Charge_Histogram_3 : 1272|32@1+ (1,0) [0|4294967295] "s" Vector__XXX
 SG_ State_of_Charge_Histogram_4 : 1304|32@1+ (1,0) [0|4294967295] "s" Vector__XXX
 SG_ State_of_Charge_Histogram_5 : 1336|32@1+ (1,0) [0|4294967295] "s" Vector__XXX
 SG_ State_of_Charge_Histogram_6 : 1368|32@1+ (1,0) [0|4294967295] "s" Vector__XXX
 SG_ State_of_Charge_Histogram_7 : 1400|32@1+ (1,0) [0|4294967295] "s" Vector__XXX
 SG_ State_of_Charge_Histogram_8 : 1432|32@1+ (1,0) [0|4294967295] "s" Vector__XXX
 SG_ State_of_Charge_Histogram_9 : 1464|32@1+ (1,0) [0|4294967295] "s" Vector__XXX
 SG_ State_of_Charge_Histogram_10 : 1496|32@1+ (1,0) [0|4294967295] "s" Vector__XXX
 SG_ State_of_Charge_Histogram_11 : 1528|32@1+ (1,0) [0|4294967295] "s" Vector__XXX
 SG_ State_of_Charge_Histogram_12 : 1560|32@1+ (1,0) [0|4294967295] "s" Vector__XXX
 SG_ State_of_Charge_Histogram_13 : 1592|32@1+ (1,0) [0|4294967295] "s" Vector__XXX
 SG_ State_of_Charge_Histogram_14 : 1624|32@1+ (1,0) [0|4294967295] "s" Vector__XXX
 SG_ State_of_Charge_Histogram_15 : 1656|32@1+ (1,0) [0|4294967295] "s" Vector__XXX
 SG_ State_of_Charge_Histogram_16 : 1688|32@1+ (1,0) [0|4294967295] "s" Vector__XXX
 SG_ State_of_Charge_Histogram_17 : 1720|32@1+ (1,0) [0|4294967295] "s" Vector__XXX
 SG_ State_of_Charge_Histogram_18 : 1752|32@1+ (1,0) [0|4294967295] "s" Vector__XXX
 SG_ State_of_Charge_Histogram_19 : 1784|32@1+ (1,0) [0|4294967295] "s" Vector__XXX

BO_ 2566852816 PropB_16_INTERPACK_Pack08BMS: 227 Pack08BMS
 SG_ Remaining_Capacity : 0|8@1+ (1,0) [0|255] "Ah" Vector__XXX
 SG_ Date_of_Manufacture_0 : 8|8@1+ (1,0) [0|255] "" Vector__XXX
 SG_ Date_of_Manufacture_1 : 16|8@1+ (1,0) [0|255] "" Vector__XXX
 SG_ Date_of_Manufacture_2 : 24|8@1+ (1,0) [0|255] "" Vector__XXX
 SG_ Date_of_Manufacture_3 : 32|8@1+ (1,0) [0|255] "" Vector__XXX
 SG_ Date_of_Manufacture_4 : 40|8@1+ (1,0) [0|255] "" Vector__XXX
 SG_ Date_of_Manufacture_5 : 48|8@1+ (1,0) [0|255] "" Vector__XXX
 SG_ Date_of_Manufacture_6 : 56|8@1+ (1,0) [0|255] "" Vector__XXX
 SG_ Date_of_Putting_Into_Service_0 : 64|8@1+ (1,0) [0|255] "" Vector__XXX
 SG_ Date_of_Putting_Into_Service_1 : 72|8@1+ (1,0) [0|255] "" Vector__XXX
 SG_ Date_of_Putting_Into_Service_2 : 80|8@1+ (1,0) [0|255] "" Vector__XXX
 SG_ Date_of_Putting_Into_Service_3 : 88|8@1+ (1,0) [0|255] "" Vector__XXX
 SG_ Date_of_Putting_Into_Service_4 : 96|8@1+ (1,0) [0|255] "" Vector__XXX
 SG_ Date_of_Putting_Into_Service_5 : 104|8@1+ (1,0) [0|255] "" Vector__XXX
 SG_ Date_of_Putting_Into_Service_6 : 112|8@1+ (1,0) [0|255] "" Vector__XXX
 SG_ Charge_Energy_Throughput : 120|24@1+ (1,0) [0|16777215] "kWh" Vector__XXX
 SG_ Discharge_Energy_Throughput : 144|24@1+ (1,0) [0|16777215] "kWh" Vector__XXX
 SG_ Total_Energy_Throughput : 168|24@1+ (1,0) [0|16777215] "kWh" Vector__XXX
 SG_ Charged_Capacity_Throughput : 192|24@1+ (1,0) [0|16777215] "Ah" Vector__XXX
 SG_ Discharged_Capacity_Throughput : 216|24@1+ (1,0) [0|16777215] "Ah" Vector__XXX
 SG_ Total_Capacity_Throughput : 240|24@1+ (1,0) [0|16777215] "Ah" Vector__XXX
 SG_ Number_of_Full_Equivalent_Charge0 : 264|16@1+ (1,0) [0|65535] "cycles" Vector__XXX
 SG_ Number_of_Full_Equivalent_Discha : 280|16@1+ (1,0) [0|65535] "cycles" Vector__XXX
 SG_ Number_of_Full_Equivalent_Charge1 : 296|16@1+ (1,0) [0|65535] "cycles" Vector__XXX
 SG_ Temperature_Histogram_0 : 312|32@1+ (1,0) [0|4294967295] "s" Vector__XXX
 SG_ Temperature_Histogram_1 : 344|32@1+ (1,0) [0|4294967295] "s" Vector__XXX
 SG_ Temperature_Histogram_2 : 376|32@1+ (1,0) [0|4294967295] "s" Vector__XXX
 SG_ Temperature_Histogram_3 : 408|32@1+ (1,0) [0|4294967295] "s" Vector__XXX
 SG_ Temperature_Histogram_4 : 440|32@1+ (1,0) [0|4294967295] "s" Vector__XXX
 SG_ Temperature_Histogram_5 : 472|32@1+ (1,0) [0|4294967295] "s" Vector__XXX
 SG_ Temperature_Histogram_6 : 504|32@1+ (1,0) [0|4294967295] "s" Vector__XXX
 SG_ Temperature_Histogram_7 : 536|32@1+ (1,0) [0|4294967295] "s" Vector__XXX
 SG_ Temperature_Histogram_8 : 568|32@1+ (1,0) [0|4294967295] "s" Vector__XXX
 SG_ Temperature_Histogram_9 : 600|32@1+ (1,0) [0|4294967295] "s" Vector__XXX
 SG_ Temperature_Histogram_10 : 632|32@1+ (1,0) [0|4294967295] "s" Vector__XXX
 SG_ Temperature_Histogram_11 : 664|32@1+ (1,0) [0|4294967295] "s" Vector__XXX
 SG_ Temperature_Histogram_12 : 696|32@1+ (1,0) [0|4294967295] "s" Vector__XXX
 SG_ Temperature_Histogram_13 : 728|32@1+ (1,0) [0|4294967295] "s" Vector__XXX
 SG_ Temperature_Histogram_14 : 760|32@1+ (1,0) [0|4294967295] "s" Vector__XXX
 SG_ Temperature_Histogram_15 : 792|32@1+ (1,0) [0|4294967295] "s" Vector__XXX
 SG_ Temperature_Histogram_16 : 824|32@1+ (1,0) [0|4294967295] "s" Vector__XXX
 SG_ Temperature_Histogram_17 : 856|32@1+ (1,0) [0|4294967295] "s" Vector__XXX
 SG_ Temperature_Histogram_18 : 888|32@1+ (1,0) [0|4294967295] "s" Vector__XXX
 SG_ Temperature_Histogram_19 : 920|32@1+ (1,0) [0|4294967295] "s" Vector__XXX
 SG_ Temperature_Histogram_20 : 952|32@1+ (1,0) [0|4294967295] "s" Vector__XXX
 SG_ Temperature_Histogram_21 : 984|32@1+ (1,0) [0|4294967295] "s" Vector__XXX
 SG_ Temperature_Histogram_22 : 1016|32@1+ (1,0) [0|4294967295] "s" Vector__XXX
 SG_ Temperature_Histogram_23 : 1048|32@1+ (1,0) [0|4294967295] "s" Vector__XXX
 SG_ Time_Spent_in_Extreme_Temperatur0 : 1080|32@1+ (1,0) [0|4294967295] "s" Vector__XXX
 SG_ Time_Spent_in_Extreme_Temperatur1 : 1112|32@1+ (1,0) [0|4294967295] "s" Vector__XXX
 SG_ Number_of_Deep_Discharge_Events : 1144|8@1+ (1,0) [0|255] "count" Vector__XXX
 SG_ Time_Spent_Charging_In_Extreme_T : 1152|8@1+ (1,0) [0|255] "s" Vector__XXX
 SG_ State_of_Charge : 1160|16@1+ (0.0015625,0) [0|102.3984375] "%" Vector__XXX
 SG_ State_of_Charge_Histogram_0 : 1176|32@1+ (1,0) [0|4294967295] "s" Vector__XXX
 SG_ State_of_Charge_Histogram_1 : 1208|32@1+ (1,0) [0|4294967295] "s" Vector__XXX
 SG_ State_of_Charge_Histogram_2 : 1240|32@1+ (1,0) [0|4294967295] "s" Vector__XXX
 SG_ State_of_Charge_Histogram_3 : 1272|32@1+ (1,0) [0|4294967295] "s" Vector__XXX
 SG_ State_of_Charge_Histogram_4 : 1304|32@1+ (1,0) [0|4294967295] "s" Vector__XXX
 SG_ State_of_Charge_Histogram_5 : 1336|32@1+ (1,0) [0|4294967295] "s" Vector__XXX
 SG_ State_of_Charge_Histogram_6 : 1368|32@1+ (1,0) [0|4294967295] "s" Vector__XXX
 SG_ State_of_Charge_Histogram_7 : 1400|32@1+ (1,0) [0|4294967295] "s" Vector__XXX
 SG_ State_of_Charge_Histogram_8 : 1432|32@1+ (1,0) [0|4294967295] "s" Vector__XXX
 SG_ State_of_Charge_Histogram_9 : 1464|32@1+ (1,0) [0|4294967295] "s" Vector__XXX
 SG_ State_of_Charge_Histogram_10 : 1496|32@1+ (1,0) [0|4294967295] "s" Vector__XXX
 SG_ State_of_Charge_Histogram_11 : 1528|32@1+ (1,0) [0|4294967295] "s" Vector__XXX
 SG_ State_of_Charge_Histogram_12 : 1560|32@1+ (1,0) [0|4294967295] "s" Vector__XXX
 SG_ State_of_Charge_Histogram_13 : 1592|32@1+ (1,0) [0|4294967295] "s" Vector__XXX
 SG_ State_of_Charge_Histogram_14 : 1624|32@1+ (1,0) [0|4294967295] "s" Vector__XXX
 SG_ State_of_Charge_Histogram_15 : 1656|32@1+ (1,0) [0|4294967295] "s" Vector__XXX
 SG_ State_of_Charge_Histogram_16 : 1688|32@1+ (1,0) [0|4294967295] "s" Vector__XXX
 SG_ State_of_Charge_Histogram_17 : 1720|32@1+ (1,0) [0|4294967295] "s" Vector__XXX
 SG_ State_of_Charge_Histogram_18 : 1752|32@1+ (1,0) [0|4294967295] "s" Vector__XXX
 SG_ State_of_Charge_Histogram_19 : 1784|32@1+ (1,0) [0|4294967295] "s" Vector__XXX

CM_ SG_ 2350631173 HVESS_High_Voltage_Bus_Connect_C "Command to connect the battery system to the HVDC bus";
CM_ SG_ 2350631173 HVESS_Charging_Mode "Communication of intent to charge from external controller";
CM_ SG_ 2364575945 HVESS_Available_Discharge_Power "Battery system available discharge power";
CM_ SG_ 2364575945 HVESS_Available_Charge_Power "Battery system available charge power";
CM_ SG_ 2364575945 HVESS_Voltage_Level "Battery system voltage";
CM_ SG_ 2364575945 HVESS_Current "Sum of all battery pack currents";
CM_ SG_ 2364607689 HVESS_Highest_Cell_State_of_Char "Battery pack ID containing SPN 8085 (HVESS_Maximum_Cell_State_of_Charge)";
CM_ SG_ 2364607689 HVESS_Lowest_Cell_State_of_Charg "Battery pack ID containing SPN 8084 (HVESS_Minimum_Cell_State_of_Charge)";
CM_ SG_ 2364607689 HVESS_High_Voltage_Bus_Passive_I "Battery system minimum isolation measurement result (any battery pack)";
CM_ SG_ 2365203657 HVESS_Estimated_Charge_Time_Rema "Battery system estimated charge time remaining";
CM_ SG_ 2364576201 HVESS_Fast_Update_State_of_Charg "Battery system state of charge";
CM_ SG_ 2364576201 HVESS_Highest_Cell_Voltage "Battery system highest cell voltage (any battery pack)";
CM_ SG_ 2364576201 HVESS_Lowest_Cell_Voltage "Battery system lowest cell voltage (any battery pack)";
CM_ SG_ 2364576457 HVESS_Highest_Cell_Temperature "Battery system highest cell temperature (any battery pack)";
CM_ SG_ 2364576457 HVESS_Lowest_Cell_Temperature "Battery system lowest cell temperature (any battery pack)";
CM_ SG_ 2364576713 HVESS_Discharge_Capacity "Ah available to be used while applying available discharge power";
CM_ SG_ 2364576713 HVESS_Charge_Capacity "Ah available to be filled while applying available charge power";
CM_ SG_ 2364576969 HVESS_Minimum_Cell_State_of_Char "Battery system minimum cell state of charge (any battery pack)";
CM_ SG_ 2364576969 HVESS_Maximum_Cell_State_of_Char "Battery system maximum cell state of charge (any battery pack)";
CM_ SG_ 2364577225 HVESS_Bus_Voltage "HVDC bus voltage";
CM_ SG_ 2364607177 HVESS_Highest_Cell_Voltage_Pack_ "Battery pack ID containing SPN 5922 (HVESS_Highest_Cell_Voltage)";
CM_ SG_ 2364607177 HVESS_Lowest_Cell_Voltage_Pack_N "Battery pack ID containing SPN 5923 (HVESS_Lowest_Cell_Voltage)";
CM_ SG_ 2364607433 HVESS_Highest_Cell_Temperature_P "Battery pack ID containing SPN 8075 (HVESS_Highest_Cell_Temperature)";
CM_ SG_ 2364607433 HVESS_Lowest_Cell_Temperature_Pa "Battery pack ID containing SPN 8076 (HVESS_Lowest_Cell_Temperature)";
CM_ SG_ 2633785033 HVESS_State_of_Health "Battery system minimum state of health (any battery pack)";
CM_ SG_ 2364577481 HVESS_High_Voltage_Bus_Disconnec "Indicates one or more battery packs in the battery system are about to disconnect from the HVDC bus due to validated fault condition";
CM_ SG_ 2364577481 HVESS_High_Voltage_Bus_Connectio "Battery system connection status to the HVDC bus";
CM_ SG_ 2364577481 HVESS_Operational_Status "Battery system operational status";
CM_ SG_ 2365522181 External_Clear_DMs_Command "Command from external controller to clear DMs";
CM_ SG_ 2365522181 Pack01_Disable_Command "Command from external controller to disable battery pack 1";
CM_ SG_ 2365522181 Pack02_Disable_Command "Command from external controller to disable battery pack 2";
CM_ SG_ 2365522181 Pack03_Disable_Command "Command from external controller to disable battery pack 3";
CM_ SG_ 2365522181 Pack04_Disable_Command "Command from external controller to disable battery pack 4";
CM_ SG_ 2365522181 Pack05_Disable_Command "Command from external controller to disable battery pack 5";
CM_ SG_ 2365522181 Pack06_Disable_Command "Command from external controller to disable battery pack 6";
CM_ SG_ 2365522181 Pack07_Disable_Command "Command from external controller to disable battery pack 7";
CM_ SG_ 2365522181 Pack08_Disable_Command "Command from external controller to disable battery pack 8";
CM_ SG_ 2365522181 Pack09_Disable_Command "Command from external controller to disable battery pack 9";
CM_ SG_ 2365522181 Pack10_Disable_Command "Command from external controller to disable battery pack 10";
CM_ SG_ 2365522181 Pack11_Disable_Command "Command from external controller to disable battery pack 11";
CM_ SG_ 2365522181 Pack12_Disable_Command "Command from external controller to disable battery pack 12";
CM_ SG_ 2365522181 Pack13_Disable_Command "Command from external controller to disable battery pack 13";
CM_ SG_ 2365522181 Pack14_Disable_Command "Command from external controller to disable battery pack 14";
CM_ SG_ 2365522181 Pack15_Disable_Command "Command from external controller to disable battery pack 15";
CM_ SG_ 2365522181 Pack16_Disable_Command "Command from external controller to disable battery pack 16";
CM_ SG_ 2365522437 Number_Packs_Configured "Communication of the number of battery packs in the battery system from external controller";
CM_ SG_ 2365523145 Number_Packs_Operational "Count of battery packs which are operational";
CM_ SG_ 2365523145 Number_Packs_Disabled_Internal "Count of battery packs which have validated a fault condition leading to an RSL DTC";
CM_ SG_ 2365523145 Number_Packs_Connected "Count of battery packs which are connected";
CM_ SG_ 2365523401 HVESS_Total_Lifetime_Energy_Inpu "Battery system total lifetime energy input";
CM_ SG_ 2365523401 HVESS_Total_Lifetime_Energy_Outp "Battery system total lifetime energy output";
CM_ SG_ 2566852809 Remaining_Capacity "Pack charge capacity";
CM_ SG_ 2566852809 Date_of_Manufacture_0 "Date of manufacture encoded as YYYY-MM";
CM_ SG_ 2566852809 Date_of_Manufacture_1 "Date of manufacture encoded as YYYY-MM";
CM_ SG_ 2566852809 Date_of_Manufacture_2 "Date of manufacture encoded as YYYY-MM";
CM_ SG_ 2566852809 Date_of_Manufacture_3 "Date of manufacture encoded as YYYY-MM";
CM_ SG_ 2566852809 Date_of_Manufacture_4 "Date of manufacture encoded as YYYY-MM";
CM_ SG_ 2566852809 Date_of_Manufacture_5 "Date of manufacture encoded as YYYY-MM";
CM_ SG_ 2566852809 Date_of_Manufacture_6 "Date of manufacture encoded as YYYY-MM";
CM_ SG_ 2566852809 Date_of_Putting_Into_Service_0 "Date of putting into service encoded as YYYY-MM";
CM_ SG_ 2566852809 Date_of_Putting_Into_Service_1 "Date of putting into service encoded as YYYY-MM";
CM_ SG_ 2566852809 Date_of_Putting_Into_Service_2 "Date of putting into service encoded as YYYY-MM";
CM_ SG_ 2566852809 Date_of_Putting_Into_Service_3 "Date of putting into service encoded as YYYY-MM";
CM_ SG_ 2566852809 Date_of_Putting_Into_Service_4 "Date of putting into service encoded as YYYY-MM";
CM_ SG_ 2566852809 Date_of_Putting_Into_Service_5 "Date of putting into service encoded as YYYY-MM";
CM_ SG_ 2566852809 Date_of_Putting_Into_Service_6 "Date of putting into service encoded as YYYY-MM";
CM_ SG_ 2566852809 Charge_Energy_Throughput "Battery system charge energy throughput";
CM_ SG_ 2566852809 Discharge_Energy_Throughput "Battery system discharge energy throughput";
CM_ SG_ 2566852809 Total_Energy_Throughput "Battery system total energy throughput";
CM_ SG_ 2566852809 Charged_Capacity_Throughput "Battery system charged capacity throughput";
CM_ SG_ 2566852809 Discharged_Capacity_Throughput "Battery system discharged capacity throughput";
CM_ SG_ 2566852809 Total_Capacity_Throughput "Battery system total capacity throughput";
CM_ SG_ 2566852809 Number_of_Full_Equivalent_Charge0 "Number of full equivalent charge cycles";
CM_ SG_ 2566852809 Number_of_Full_Equivalent_Discha "Number of full equivalent discharge cycles";
CM_ SG_ 2566852809 Number_of_Full_Equivalent_Charge1 "Number of full equivalent charge-discharge cycles";
CM_ SG_ 2566852809 Temperature_Histogram_0 "Battery system temperature histogram (seconds) of the battery pack.";
CM_ SG_ 2566852809 Temperature_Histogram_1 "Battery system temperature histogram (seconds) of the battery pack.";
CM_ SG_ 2566852809 Temperature_Histogram_2 "Battery system temperature histogram (seconds) of the battery pack.";
CM_ SG_ 2566852809 Temperature_Histogram_3 "Battery system temperature histogram (seconds) of the battery pack.";
CM_ SG_ 2566852809 Temperature_Histogram_4 "Battery system temperature histogram (seconds) of the battery pack.";
CM_ SG_ 2566852809 Temperature_Histogram_5 "Battery system temperature histogram (seconds) of the battery pack.";
CM_ SG_ 2566852809 Temperature_Histogram_6 "Battery system temperature histogram (seconds) of the battery pack.";
CM_ SG_ 2566852809 Temperature_Histogram_7 "Battery system temperature histogram (seconds) of the battery pack.";
CM_ SG_ 2566852809 Temperature_Histogram_8 "Battery system temperature histogram (seconds) of the battery pack.";
CM_ SG_ 2566852809 Temperature_Histogram_9 "Battery system temperature histogram (seconds) of the battery pack.";
CM_ SG_ 2566852809 Temperature_Histogram_10 "Battery system temperature histogram (seconds) of the battery pack.";
CM_ SG_ 2566852809 Temperature_Histogram_11 "Battery system temperature histogram (seconds) of the battery pack.";
CM_ SG_ 2566852809 Temperature_Histogram_12 "Battery system temperature histogram (seconds) of the battery pack.";
CM_ SG_ 2566852809 Temperature_Histogram_13 "Battery system temperature histogram (seconds) of the battery pack.";
CM_ SG_ 2566852809 Temperature_Histogram_14 "Battery system temperature histogram (seconds) of the battery pack.";
CM_ SG_ 2566852809 Temperature_Histogram_15 "Battery system temperature histogram (seconds) of the battery pack.";
CM_ SG_ 2566852809 Temperature_Histogram_16 "Battery system temperature histogram (seconds) of the battery pack.";
CM_ SG_ 2566852809 Temperature_Histogram_17 "Battery system temperature histogram (seconds) of the battery pack.";
CM_ SG_ 2566852809 Temperature_Histogram_18 "Battery system temperature histogram (seconds) of the battery pack.";
CM_ SG_ 2566852809 Temperature_Histogram_19 "Battery system temperature histogram (seconds) of the battery pack.";
CM_ SG_ 2566852809 Temperature_Histogram_20 "Battery system temperature histogram (seconds) of the battery pack.";
CM_ SG_ 2566852809 Temperature_Histogram_21 "Battery system temperature histogram (seconds) of the battery pack.";
CM_ SG_ 2566852809 Temperature_Histogram_22 "Battery system temperature histogram (seconds) of the battery pack.";
CM_ SG_ 2566852809 Temperature_Histogram_23 "Battery system temperature histogram (seconds) of the battery pack.";
CM_ SG_ 2566852809 Time_Spent_in_Extreme_Temperatur0 "Time spent in extreme temperatures above boundary (seconds) of the battery pack.";
CM_ SG_ 2566852809 Time_Spent_in_Extreme_Temperatur1 "Time spent in extreme temperatures below boundary (seconds) of the battery pack.";
CM_ SG_ 2566852809 Number_of_Deep_Discharge_Events "Number of deep discharge events of the battery pack.";
CM_ SG_ 2566852809 Time_Spent_Charging_In_Extreme_T "Time spent charging in extreme temperatures (seconds) of the battery pack.";
CM_ SG_ 2566852809 State_of_Charge "Battery system state of charge";
CM_ SG_ 2566852809 State_of_Charge_Histogram_0 "Battery system state of charge histogram (seconds) of the battery pack.";
CM_ SG_ 2566852809 State_of_Charge_Histogram_1 "Battery system state of charge histogram (seconds) of the battery pack.";
CM_ SG_ 2566852809 State_of_Charge_Histogram_2 "Battery system state of charge histogram (seconds) of the battery pack.";
CM_ SG_ 2566852809 State_of_Charge_Histogram_3 "Battery system state of charge histogram (seconds) of the battery pack.";
CM_ SG_ 2566852809 State_of_Charge_Histogram_4 "Battery system state of charge histogram (seconds) of the battery pack.";
CM_ SG_ 2566852809 State_of_Charge_Histogram_5 "Battery system state of charge histogram (seconds) of the battery pack.";
CM_ SG_ 2566852809 State_of_Charge_Histogram_6 "Battery system state of charge histogram (seconds) of the battery pack.";
CM_ SG_ 2566852809 State_of_Charge_Histogram_7 "Battery system state of charge histogram (seconds) of the battery pack.";
CM_ SG_ 2566852809 State_of_Charge_Histogram_8 "Battery system state of charge histogram (seconds) of the battery pack.";
CM_ SG_ 2566852809 State_of_Charge_Histogram_9 "Battery system state of charge histogram (seconds) of the battery pack.";
CM_ SG_ 2566852809 State_of_Charge_Histogram_10 "Battery system state of charge histogram (seconds) of the battery pack.";
CM_ SG_ 2566852809 State_of_Charge_Histogram_11 "Battery system state of charge histogram (seconds) of the battery pack.";
CM_ SG_ 2566852809 State_of_Charge_Histogram_12 "Battery system state of charge histogram (seconds) of the battery pack.";
CM_ SG_ 2566852809 State_of_Charge_Histogram_13 "Battery system state of charge histogram (seconds) of the battery pack.";
CM_ SG_ 2566852809 State_of_Charge_Histogram_14 "Battery system state of charge histogram (seconds) of the battery pack.";
CM_ SG_ 2566852809 State_of_Charge_Histogram_15 "Battery system state of charge histogram (seconds) of the battery pack.";
CM_ SG_ 2566852809 State_of_Charge_Histogram_16 "Battery system state of charge histogram (seconds) of the battery pack.";
CM_ SG_ 2566852809 State_of_Charge_Histogram_17 "Battery system state of charge histogram (seconds) of the battery pack.";
CM_ SG_ 2566852809 State_of_Charge_Histogram_18 "Battery system state of charge histogram (seconds) of the battery pack.";
CM_ SG_ 2566852809 State_of_Charge_Histogram_19 "Battery system state of charge histogram (seconds) of the battery pack.";
CM_ SG_ 2365526473 HVESS_Pulse_Discharge_Counter "System high discharge power mode time counter";
CM_ SG_ 2365526473 HVESS_Pulse_Charge_Counter "System high charge power mode time counter";
CM_ SG_ 2365526473 HVESS_Available_Pulse_Discharge_ "Available discharge pulse power";
CM_ SG_ 2365526473 HVESS_Available_Pulse_Charge_Pow "Available charge pulse power";
CM_ SG_ 2365526729 HVESS_Available_Discharge_Curren "Available system discharge current based on Leader SOP";
CM_ SG_ 2365526729 HVESS_Available_Charge_Current "Available system charge current based on Leader SOP";
CM_ SG_ 2365526729 HVESS_Available_Pulse_Discharge_ "Available system discharge pulse current based on Leader SOP";
CM_ SG_ 2365526729 HVESS_Available_Pulse_Charge_Cur "Available system charge pulse current based on Leader SOP";
CM_ SG_ 2365526985 HVESS_Current_Extended_Range "Sum of all battery pack currents";
CM_ SG_ 2566852810 Remaining_Capacity "Pack charge capacity";
CM_ SG_ 2566852810 Date_of_Manufacture_0 "Date of manufacture encoded as YYYY-MM";
CM_ SG_ 2566852810 Date_of_Manufacture_1 "Date of manufacture encoded as YYYY-MM";
CM_ SG_ 2566852810 Date_of_Manufacture_2 "Date of manufacture encoded as YYYY-MM";
CM_ SG_ 2566852810 Date_of_Manufacture_3 "Date of manufacture encoded as YYYY-MM";
CM_ SG_ 2566852810 Date_of_Manufacture_4 "Date of manufacture encoded as YYYY-MM";
CM_ SG_ 2566852810 Date_of_Manufacture_5 "Date of manufacture encoded as YYYY-MM";
CM_ SG_ 2566852810 Date_of_Manufacture_6 "Date of manufacture encoded as YYYY-MM";
CM_ SG_ 2566852810 Date_of_Putting_Into_Service_0 "Date of putting into service encoded as YYYY-MM";
CM_ SG_ 2566852810 Date_of_Putting_Into_Service_1 "Date of putting into service encoded as YYYY-MM";
CM_ SG_ 2566852810 Date_of_Putting_Into_Service_2 "Date of putting into service encoded as YYYY-MM";
CM_ SG_ 2566852810 Date_of_Putting_Into_Service_3 "Date of putting into service encoded as YYYY-MM";
CM_ SG_ 2566852810 Date_of_Putting_Into_Service_4 "Date of putting into service encoded as YYYY-MM";
CM_ SG_ 2566852810 Date_of_Putting_Into_Service_5 "Date of putting into service encoded as YYYY-MM";
CM_ SG_ 2566852810 Date_of_Putting_Into_Service_6 "Date of putting into service encoded as YYYY-MM";
CM_ SG_ 2566852810 Charge_Energy_Throughput "Battery system charge energy throughput";
CM_ SG_ 2566852810 Discharge_Energy_Throughput "Battery system discharge energy throughput";
CM_ SG_ 2566852810 Total_Energy_Throughput "Battery system total energy throughput";
CM_ SG_ 2566852810 Charged_Capacity_Throughput "Battery system charged capacity throughput";
CM_ SG_ 2566852810 Discharged_Capacity_Throughput "Battery system discharged capacity throughput";
CM_ SG_ 2566852810 Total_Capacity_Throughput "Battery system total capacity throughput";
CM_ SG_ 2566852810 Number_of_Full_Equivalent_Charge0 "Number of full equivalent charge cycles";
CM_ SG_ 2566852810 Number_of_Full_Equivalent_Discha "Number of full equivalent discharge cycles";
CM_ SG_ 2566852810 Number_of_Full_Equivalent_Charge1 "Number of full equivalent charge-discharge cycles";
CM_ SG_ 2566852810 Temperature_Histogram_0 "Battery system temperature histogram (seconds) of the battery pack.";
CM_ SG_ 2566852810 Temperature_Histogram_1 "Battery system temperature histogram (seconds) of the battery pack.";
CM_ SG_ 2566852810 Temperature_Histogram_2 "Battery system temperature histogram (seconds) of the battery pack.";
CM_ SG_ 2566852810 Temperature_Histogram_3 "Battery system temperature histogram (seconds) of the battery pack.";
CM_ SG_ 2566852810 Temperature_Histogram_4 "Battery system temperature histogram (seconds) of the battery pack.";
CM_ SG_ 2566852810 Temperature_Histogram_5 "Battery system temperature histogram (seconds) of the battery pack.";
CM_ SG_ 2566852810 Temperature_Histogram_6 "Battery system temperature histogram (seconds) of the battery pack.";
CM_ SG_ 2566852810 Temperature_Histogram_7 "Battery system temperature histogram (seconds) of the battery pack.";
CM_ SG_ 2566852810 Temperature_Histogram_8 "Battery system temperature histogram (seconds) of the battery pack.";
CM_ SG_ 2566852810 Temperature_Histogram_9 "Battery system temperature histogram (seconds) of the battery pack.";
CM_ SG_ 2566852810 Temperature_Histogram_10 "Battery system temperature histogram (seconds) of the battery pack.";
CM_ SG_ 2566852810 Temperature_Histogram_11 "Battery system temperature histogram (seconds) of the battery pack.";
CM_ SG_ 2566852810 Temperature_Histogram_12 "Battery system temperature histogram (seconds) of the battery pack.";
CM_ SG_ 2566852810 Temperature_Histogram_13 "Battery system temperature histogram (seconds) of the battery pack.";
CM_ SG_ 2566852810 Temperature_Histogram_14 "Battery system temperature histogram (seconds) of the battery pack.";
CM_ SG_ 2566852810 Temperature_Histogram_15 "Battery system temperature histogram (seconds) of the battery pack.";
CM_ SG_ 2566852810 Temperature_Histogram_16 "Battery system temperature histogram (seconds) of the battery pack.";
CM_ SG_ 2566852810 Temperature_Histogram_17 "Battery system temperature histogram (seconds) of the battery pack.";
CM_ SG_ 2566852810 Temperature_Histogram_18 "Battery system temperature histogram (seconds) of the battery pack.";
CM_ SG_ 2566852810 Temperature_Histogram_19 "Battery system temperature histogram (seconds) of the battery pack.";
CM_ SG_ 2566852810 Temperature_Histogram_20 "Battery system temperature histogram (seconds) of the battery pack.";
CM_ SG_ 2566852810 Temperature_Histogram_21 "Battery system temperature histogram (seconds) of the battery pack.";
CM_ SG_ 2566852810 Temperature_Histogram_22 "Battery system temperature histogram (seconds) of the battery pack.";
CM_ SG_ 2566852810 Temperature_Histogram_23 "Battery system temperature histogram (seconds) of the battery pack.";
CM_ SG_ 2566852810 Time_Spent_in_Extreme_Temperatur0 "Time spent in extreme temperatures above boundary (seconds) of the battery pack.";
CM_ SG_ 2566852810 Time_Spent_in_Extreme_Temperatur1 "Time spent in extreme temperatures below boundary (seconds) of the battery pack.";
CM_ SG_ 2566852810 Number_of_Deep_Discharge_Events "Number of deep discharge events of the battery pack.";
CM_ SG_ 2566852810 Time_Spent_Charging_In_Extreme_T "Time spent charging in extreme temperatures (seconds) of the battery pack.";
CM_ SG_ 2566852810 State_of_Charge "Battery system state of charge";
CM_ SG_ 2566852810 State_of_Charge_Histogram_0 "Battery system state of charge histogram (seconds) of the battery pack.";
CM_ SG_ 2566852810 State_of_Charge_Histogram_1 "Battery system state of charge histogram (seconds) of the battery pack.";
CM_ SG_ 2566852810 State_of_Charge_Histogram_2 "Battery system state of charge histogram (seconds) of the battery pack.";
CM_ SG_ 2566852810 State_of_Charge_Histogram_3 "Battery system state of charge histogram (seconds) of the battery pack.";
CM_ SG_ 2566852810 State_of_Charge_Histogram_4 "Battery system state of charge histogram (seconds) of the battery pack.";
CM_ SG_ 2566852810 State_of_Charge_Histogram_5 "Battery system state of charge histogram (seconds) of the battery pack.";
CM_ SG_ 2566852810 State_of_Charge_Histogram_6 "Battery system state of charge histogram (seconds) of the battery pack.";
CM_ SG_ 2566852810 State_of_Charge_Histogram_7 "Battery system state of charge histogram (seconds) of the battery pack.";
CM_ SG_ 2566852810 State_of_Charge_Histogram_8 "Battery system state of charge histogram (seconds) of the battery pack.";
CM_ SG_ 2566852810 State_of_Charge_Histogram_9 "Battery system state of charge histogram (seconds) of the battery pack.";
CM_ SG_ 2566852810 State_of_Charge_Histogram_10 "Battery system state of charge histogram (seconds) of the battery pack.";
CM_ SG_ 2566852810 State_of_Charge_Histogram_11 "Battery system state of charge histogram (seconds) of the battery pack.";
CM_ SG_ 2566852810 State_of_Charge_Histogram_12 "Battery system state of charge histogram (seconds) of the battery pack.";
CM_ SG_ 2566852810 State_of_Charge_Histogram_13 "Battery system state of charge histogram (seconds) of the battery pack.";
CM_ SG_ 2566852810 State_of_Charge_Histogram_14 "Battery system state of charge histogram (seconds) of the battery pack.";
CM_ SG_ 2566852810 State_of_Charge_Histogram_15 "Battery system state of charge histogram (seconds) of the battery pack.";
CM_ SG_ 2566852810 State_of_Charge_Histogram_16 "Battery system state of charge histogram (seconds) of the battery pack.";
CM_ SG_ 2566852810 State_of_Charge_Histogram_17 "Battery system state of charge histogram (seconds) of the battery pack.";
CM_ SG_ 2566852810 State_of_Charge_Histogram_18 "Battery system state of charge histogram (seconds) of the battery pack.";
CM_ SG_ 2566852810 State_of_Charge_Histogram_19 "Battery system state of charge histogram (seconds) of the battery pack.";
CM_ SG_ 2566852811 Remaining_Capacity "Pack charge capacity";
CM_ SG_ 2566852811 Date_of_Manufacture_0 "Date of manufacture encoded as YYYY-MM";
CM_ SG_ 2566852811 Date_of_Manufacture_1 "Date of manufacture encoded as YYYY-MM";
CM_ SG_ 2566852811 Date_of_Manufacture_2 "Date of manufacture encoded as YYYY-MM";
CM_ SG_ 2566852811 Date_of_Manufacture_3 "Date of manufacture encoded as YYYY-MM";
CM_ SG_ 2566852811 Date_of_Manufacture_4 "Date of manufacture encoded as YYYY-MM";
CM_ SG_ 2566852811 Date_of_Manufacture_5 "Date of manufacture encoded as YYYY-MM";
CM_ SG_ 2566852811 Date_of_Manufacture_6 "Date of manufacture encoded as YYYY-MM";
CM_ SG_ 2566852811 Date_of_Putting_Into_Service_0 "Date of putting into service encoded as YYYY-MM";
CM_ SG_ 2566852811 Date_of_Putting_Into_Service_1 "Date of putting into service encoded as YYYY-MM";
CM_ SG_ 2566852811 Date_of_Putting_Into_Service_2 "Date of putting into service encoded as YYYY-MM";
CM_ SG_ 2566852811 Date_of_Putting_Into_Service_3 "Date of putting into service encoded as YYYY-MM";
CM_ SG_ 2566852811 Date_of_Putting_Into_Service_4 "Date of putting into service encoded as YYYY-MM";
CM_ SG_ 2566852811 Date_of_Putting_Into_Service_5 "Date of putting into service encoded as YYYY-MM";
CM_ SG_ 2566852811 Date_of_Putting_Into_Service_6 "Date of putting into service encoded as YYYY-MM";
CM_ SG_ 2566852811 Charge_Energy_Throughput "Battery system charge energy throughput";
CM_ SG_ 2566852811 Discharge_Energy_Throughput "Battery system discharge energy throughput";
CM_ SG_ 2566852811 Total_Energy_Throughput "Battery system total energy throughput";
CM_ SG_ 2566852811 Charged_Capacity_Throughput "Battery system charged capacity throughput";
CM_ SG_ 2566852811 Discharged_Capacity_Throughput "Battery system discharged capacity throughput";
CM_ SG_ 2566852811 Total_Capacity_Throughput "Battery system total capacity throughput";
CM_ SG_ 2566852811 Number_of_Full_Equivalent_Charge0 "Number of full equivalent charge cycles";
CM_ SG_ 2566852811 Number_of_Full_Equivalent_Discha "Number of full equivalent discharge cycles";
CM_ SG_ 2566852811 Number_of_Full_Equivalent_Charge1 "Number of full equivalent charge-discharge cycles";
CM_ SG_ 2566852811 Temperature_Histogram_0 "Battery system temperature histogram (seconds) of the battery pack.";
CM_ SG_ 2566852811 Temperature_Histogram_1 "Battery system temperature histogram (seconds) of the battery pack.";
CM_ SG_ 2566852811 Temperature_Histogram_2 "Battery system temperature histogram (seconds) of the battery pack.";
CM_ SG_ 2566852811 Temperature_Histogram_3 "Battery system temperature histogram (seconds) of the battery pack.";
CM_ SG_ 2566852811 Temperature_Histogram_4 "Battery system temperature histogram (seconds) of the battery pack.";
CM_ SG_ 2566852811 Temperature_Histogram_5 "Battery system temperature histogram (seconds) of the battery pack.";
CM_ SG_ 2566852811 Temperature_Histogram_6 "Battery system temperature histogram (seconds) of the battery pack.";
CM_ SG_ 2566852811 Temperature_Histogram_7 "Battery system temperature histogram (seconds) of the battery pack.";
CM_ SG_ 2566852811 Temperature_Histogram_8 "Battery system temperature histogram (seconds) of the battery pack.";
CM_ SG_ 2566852811 Temperature_Histogram_9 "Battery system temperature histogram (seconds) of the battery pack.";
CM_ SG_ 2566852811 Temperature_Histogram_10 "Battery system temperature histogram (seconds) of the battery pack.";
CM_ SG_ 2566852811 Temperature_Histogram_11 "Battery system temperature histogram (seconds) of the battery pack.";
CM_ SG_ 2566852811 Temperature_Histogram_12 "Battery system temperature histogram (seconds) of the battery pack.";
CM_ SG_ 2566852811 Temperature_Histogram_13 "Battery system temperature histogram (seconds) of the battery pack.";
CM_ SG_ 2566852811 Temperature_Histogram_14 "Battery system temperature histogram (seconds) of the battery pack.";
CM_ SG_ 2566852811 Temperature_Histogram_15 "Battery system temperature histogram (seconds) of the battery pack.";
CM_ SG_ 2566852811 Temperature_Histogram_16 "Battery system temperature histogram (seconds) of the battery pack.";
CM_ SG_ 2566852811 Temperature_Histogram_17 "Battery system temperature histogram (seconds) of the battery pack.";
CM_ SG_ 2566852811 Temperature_Histogram_18 "Battery system temperature histogram (seconds) of the battery pack.";
CM_ SG_ 2566852811 Temperature_Histogram_19 "Battery system temperature histogram (seconds) of the battery pack.";
CM_ SG_ 2566852811 Temperature_Histogram_20 "Battery system temperature histogram (seconds) of the battery pack.";
CM_ SG_ 2566852811 Temperature_Histogram_21 "Battery system temperature histogram (seconds) of the battery pack.";
CM_ SG_ 2566852811 Temperature_Histogram_22 "Battery system temperature histogram (seconds) of the battery pack.";
CM_ SG_ 2566852811 Temperature_Histogram_23 "Battery system temperature histogram (seconds) of the battery pack.";
CM_ SG_ 2566852811 Time_Spent_in_Extreme_Temperatur0 "Time spent in extreme temperatures above boundary (seconds) of the battery pack.";
CM_ SG_ 2566852811 Time_Spent_in_Extreme_Temperatur1 "Time spent in extreme temperatures below boundary (seconds) of the battery pack.";
CM_ SG_ 2566852811 Number_of_Deep_Discharge_Events "Number of deep discharge events of the battery pack.";
CM_ SG_ 2566852811 Time_Spent_Charging_In_Extreme_T "Time spent charging in extreme temperatures (seconds) of the battery pack.";
CM_ SG_ 2566852811 State_of_Charge "Battery system state of charge";
CM_ SG_ 2566852811 State_of_Charge_Histogram_0 "Battery system state of charge histogram (seconds) of the battery pack.";
CM_ SG_ 2566852811 State_of_Charge_Histogram_1 "Battery system state of charge histogram (seconds) of the battery pack.";
CM_ SG_ 2566852811 State_of_Charge_Histogram_2 "Battery system state of charge histogram (seconds) of the battery pack.";
CM_ SG_ 2566852811 State_of_Charge_Histogram_3 "Battery system state of charge histogram (seconds) of the battery pack.";
CM_ SG_ 2566852811 State_of_Charge_Histogram_4 "Battery system state of charge histogram (seconds) of the battery pack.";
CM_ SG_ 2566852811 State_of_Charge_Histogram_5 "Battery system state of charge histogram (seconds) of the battery pack.";
CM_ SG_ 2566852811 State_of_Charge_Histogram_6 "Battery system state of charge histogram (seconds) of the battery pack.";
CM_ SG_ 2566852811 State_of_Charge_Histogram_7 "Battery system state of charge histogram (seconds) of the battery pack.";
CM_ SG_ 2566852811 State_of_Charge_Histogram_8 "Battery system state of charge histogram (seconds) of the battery pack.";
CM_ SG_ 2566852811 State_of_Charge_Histogram_9 "Battery system state of charge histogram (seconds) of the battery pack.";
CM_ SG_ 2566852811 State_of_Charge_Histogram_10 "Battery system state of charge histogram (seconds) of the battery pack.";
CM_ SG_ 2566852811 State_of_Charge_Histogram_11 "Battery system state of charge histogram (seconds) of the battery pack.";
CM_ SG_ 2566852811 State_of_Charge_Histogram_12 "Battery system state of charge histogram (seconds) of the battery pack.";
CM_ SG_ 2566852811 State_of_Charge_Histogram_13 "Battery system state of charge histogram (seconds) of the battery pack.";
CM_ SG_ 2566852811 State_of_Charge_Histogram_14 "Battery system state of charge histogram (seconds) of the battery pack.";
CM_ SG_ 2566852811 State_of_Charge_Histogram_15 "Battery system state of charge histogram (seconds) of the battery pack.";
CM_ SG_ 2566852811 State_of_Charge_Histogram_16 "Battery system state of charge histogram (seconds) of the battery pack.";
CM_ SG_ 2566852811 State_of_Charge_Histogram_17 "Battery system state of charge histogram (seconds) of the battery pack.";
CM_ SG_ 2566852811 State_of_Charge_Histogram_18 "Battery system state of charge histogram (seconds) of the battery pack.";
CM_ SG_ 2566852811 State_of_Charge_Histogram_19 "Battery system state of charge histogram (seconds) of the battery pack.";
CM_ SG_ 2566852812 Remaining_Capacity "Pack charge capacity";
CM_ SG_ 2566852812 Date_of_Manufacture_0 "Date of manufacture encoded as YYYY-MM";
CM_ SG_ 2566852812 Date_of_Manufacture_1 "Date of manufacture encoded as YYYY-MM";
CM_ SG_ 2566852812 Date_of_Manufacture_2 "Date of manufacture encoded as YYYY-MM";
CM_ SG_ 2566852812 Date_of_Manufacture_3 "Date of manufacture encoded as YYYY-MM";
CM_ SG_ 2566852812 Date_of_Manufacture_4 "Date of manufacture encoded as YYYY-MM";
CM_ SG_ 2566852812 Date_of_Manufacture_5 "Date of manufacture encoded as YYYY-MM";
CM_ SG_ 2566852812 Date_of_Manufacture_6 "Date of manufacture encoded as YYYY-MM";
CM_ SG_ 2566852812 Date_of_Putting_Into_Service_0 "Date of putting into service encoded as YYYY-MM";
CM_ SG_ 2566852812 Date_of_Putting_Into_Service_1 "Date of putting into service encoded as YYYY-MM";
CM_ SG_ 2566852812 Date_of_Putting_Into_Service_2 "Date of putting into service encoded as YYYY-MM";
CM_ SG_ 2566852812 Date_of_Putting_Into_Service_3 "Date of putting into service encoded as YYYY-MM";
CM_ SG_ 2566852812 Date_of_Putting_Into_Service_4 "Date of putting into service encoded as YYYY-MM";
CM_ SG_ 2566852812 Date_of_Putting_Into_Service_5 "Date of putting into service encoded as YYYY-MM";
CM_ SG_ 2566852812 Date_of_Putting_Into_Service_6 "Date of putting into service encoded as YYYY-MM";
CM_ SG_ 2566852812 Charge_Energy_Throughput "Battery system charge energy throughput";
CM_ SG_ 2566852812 Discharge_Energy_Throughput "Battery system discharge energy throughput";
CM_ SG_ 2566852812 Total_Energy_Throughput "Battery system total energy throughput";
CM_ SG_ 2566852812 Charged_Capacity_Throughput "Battery system charged capacity throughput";
CM_ SG_ 2566852812 Discharged_Capacity_Throughput "Battery system discharged capacity throughput";
CM_ SG_ 2566852812 Total_Capacity_Throughput "Battery system total capacity throughput";
CM_ SG_ 2566852812 Number_of_Full_Equivalent_Charge0 "Number of full equivalent charge cycles";
CM_ SG_ 2566852812 Number_of_Full_Equivalent_Discha "Number of full equivalent discharge cycles";
CM_ SG_ 2566852812 Number_of_Full_Equivalent_Charge1 "Number of full equivalent charge-discharge cycles";
CM_ SG_ 2566852812 Temperature_Histogram_0 "Battery system temperature histogram (seconds) of the battery pack.";
CM_ SG_ 2566852812 Temperature_Histogram_1 "Battery system temperature histogram (seconds) of the battery pack.";
CM_ SG_ 2566852812 Temperature_Histogram_2 "Battery system temperature histogram (seconds) of the battery pack.";
CM_ SG_ 2566852812 Temperature_Histogram_3 "Battery system temperature histogram (seconds) of the battery pack.";
CM_ SG_ 2566852812 Temperature_Histogram_4 "Battery system temperature histogram (seconds) of the battery pack.";
CM_ SG_ 2566852812 Temperature_Histogram_5 "Battery system temperature histogram (seconds) of the battery pack.";
CM_ SG_ 2566852812 Temperature_Histogram_6 "Battery system temperature histogram (seconds) of the battery pack.";
CM_ SG_ 2566852812 Temperature_Histogram_7 "Battery system temperature histogram (seconds) of the battery pack.";
CM_ SG_ 2566852812 Temperature_Histogram_8 "Battery system temperature histogram (seconds) of the battery pack.";
CM_ SG_ 2566852812 Temperature_Histogram_9 "Battery system temperature histogram (seconds) of the battery pack.";
CM_ SG_ 2566852812 Temperature_Histogram_10 "Battery system temperature histogram (seconds) of the battery pack.";
CM_ SG_ 2566852812 Temperature_Histogram_11 "Battery system temperature histogram (seconds) of the battery pack.";
CM_ SG_ 2566852812 Temperature_Histogram_12 "Battery system temperature histogram (seconds) of the battery pack.";
CM_ SG_ 2566852812 Temperature_Histogram_13 "Battery system temperature histogram (seconds) of the battery pack.";
CM_ SG_ 2566852812 Temperature_Histogram_14 "Battery system temperature histogram (seconds) of the battery pack.";
CM_ SG_ 2566852812 Temperature_Histogram_15 "Battery system temperature histogram (seconds) of the battery pack.";
CM_ SG_ 2566852812 Temperature_Histogram_16 "Battery system temperature histogram (seconds) of the battery pack.";
CM_ SG_ 2566852812 Temperature_Histogram_17 "Battery system temperature histogram (seconds) of the battery pack.";
CM_ SG_ 2566852812 Temperature_Histogram_18 "Battery system temperature histogram (seconds) of the battery pack.";
CM_ SG_ 2566852812 Temperature_Histogram_19 "Battery system temperature histogram (seconds) of the battery pack.";
CM_ SG_ 2566852812 Temperature_Histogram_20 "Battery system temperature histogram (seconds) of the battery pack.";
CM_ SG_ 2566852812 Temperature_Histogram_21 "Battery system temperature histogram (seconds) of the battery pack.";
CM_ SG_ 2566852812 Temperature_Histogram_22 "Battery system temperature histogram (seconds) of the battery pack.";
CM_ SG_ 2566852812 Temperature_Histogram_23 "Battery system temperature histogram (seconds) of the battery pack.";
CM_ SG_ 2566852812 Time_Spent_in_Extreme_Temperatur0 "Time spent in extreme temperatures above boundary (seconds) of the battery pack.";
CM_ SG_ 2566852812 Time_Spent_in_Extreme_Temperatur1 "Time spent in extreme temperatures below boundary (seconds) of the battery pack.";
CM_ SG_ 2566852812 Number_of_Deep_Discharge_Events "Number of deep discharge events of the battery pack.";
CM_ SG_ 2566852812 Time_Spent_Charging_In_Extreme_T "Time spent charging in extreme temperatures (seconds) of the battery pack.";
CM_ SG_ 2566852812 State_of_Charge "Battery system state of charge";
CM_ SG_ 2566852812 State_of_Charge_Histogram_0 "Battery system state of charge histogram (seconds) of the battery pack.";
CM_ SG_ 2566852812 State_of_Charge_Histogram_1 "Battery system state of charge histogram (seconds) of the battery pack.";
CM_ SG_ 2566852812 State_of_Charge_Histogram_2 "Battery system state of charge histogram (seconds) of the battery pack.";
CM_ SG_ 2566852812 State_of_Charge_Histogram_3 "Battery system state of charge histogram (seconds) of the battery pack.";
CM_ SG_ 2566852812 State_of_Charge_Histogram_4 "Battery system state of charge histogram (seconds) of the battery pack.";
CM_ SG_ 2566852812 State_of_Charge_Histogram_5 "Battery system state of charge histogram (seconds) of the battery pack.";
CM_ SG_ 2566852812 State_of_Charge_Histogram_6 "Battery system state of charge histogram (seconds) of the battery pack.";
CM_ SG_ 2566852812 State_of_Charge_Histogram_7 "Battery system state of charge histogram (seconds) of the battery pack.";
CM_ SG_ 2566852812 State_of_Charge_Histogram_8 "Battery system state of charge histogram (seconds) of the battery pack.";
CM_ SG_ 2566852812 State_of_Charge_Histogram_9 "Battery system state of charge histogram (seconds) of the battery pack.";
CM_ SG_ 2566852812 State_of_Charge_Histogram_10 "Battery system state of charge histogram (seconds) of the battery pack.";
CM_ SG_ 2566852812 State_of_Charge_Histogram_11 "Battery system state of charge histogram (seconds) of the battery pack.";
CM_ SG_ 2566852812 State_of_Charge_Histogram_12 "Battery system state of charge histogram (seconds) of the battery pack.";
CM_ SG_ 2566852812 State_of_Charge_Histogram_13 "Battery system state of charge histogram (seconds) of the battery pack.";
CM_ SG_ 2566852812 State_of_Charge_Histogram_14 "Battery system state of charge histogram (seconds) of the battery pack.";
CM_ SG_ 2566852812 State_of_Charge_Histogram_15 "Battery system state of charge histogram (seconds) of the battery pack.";
CM_ SG_ 2566852812 State_of_Charge_Histogram_16 "Battery system state of charge histogram (seconds) of the battery pack.";
CM_ SG_ 2566852812 State_of_Charge_Histogram_17 "Battery system state of charge histogram (seconds) of the battery pack.";
CM_ SG_ 2566852812 State_of_Charge_Histogram_18 "Battery system state of charge histogram (seconds) of the battery pack.";
CM_ SG_ 2566852812 State_of_Charge_Histogram_19 "Battery system state of charge histogram (seconds) of the battery pack.";
CM_ SG_ 2566852813 Remaining_Capacity "Pack charge capacity";
CM_ SG_ 2566852813 Date_of_Manufacture_0 "Date of manufacture encoded as YYYY-MM";
CM_ SG_ 2566852813 Date_of_Manufacture_1 "Date of manufacture encoded as YYYY-MM";
CM_ SG_ 2566852813 Date_of_Manufacture_2 "Date of manufacture encoded as YYYY-MM";
CM_ SG_ 2566852813 Date_of_Manufacture_3 "Date of manufacture encoded as YYYY-MM";
CM_ SG_ 2566852813 Date_of_Manufacture_4 "Date of manufacture encoded as YYYY-MM";
CM_ SG_ 2566852813 Date_of_Manufacture_5 "Date of manufacture encoded as YYYY-MM";
CM_ SG_ 2566852813 Date_of_Manufacture_6 "Date of manufacture encoded as YYYY-MM";
CM_ SG_ 2566852813 Date_of_Putting_Into_Service_0 "Date of putting into service encoded as YYYY-MM";
CM_ SG_ 2566852813 Date_of_Putting_Into_Service_1 "Date of putting into service encoded as YYYY-MM";
CM_ SG_ 2566852813 Date_of_Putting_Into_Service_2 "Date of putting into service encoded as YYYY-MM";
CM_ SG_ 2566852813 Date_of_Putting_Into_Service_3 "Date of putting into service encoded as YYYY-MM";
CM_ SG_ 2566852813 Date_of_Putting_Into_Service_4 "Date of putting into service encoded as YYYY-MM";
CM_ SG_ 2566852813 Date_of_Putting_Into_Service_5 "Date of putting into service encoded as YYYY-MM";
CM_ SG_ 2566852813 Date_of_Putting_Into_Service_6 "Date of putting into service encoded as YYYY-MM";
CM_ SG_ 2566852813 Charge_Energy_Throughput "Battery system charge energy throughput";
CM_ SG_ 2566852813 Discharge_Energy_Throughput "Battery system discharge energy throughput";
CM_ SG_ 2566852813 Total_Energy_Throughput "Battery system total energy throughput";
CM_ SG_ 2566852813 Charged_Capacity_Throughput "Battery system charged capacity throughput";
CM_ SG_ 2566852813 Discharged_Capacity_Throughput "Battery system discharged capacity throughput";
CM_ SG_ 2566852813 Total_Capacity_Throughput "Battery system total capacity throughput";
CM_ SG_ 2566852813 Number_of_Full_Equivalent_Charge0 "Number of full equivalent charge cycles";
CM_ SG_ 2566852813 Number_of_Full_Equivalent_Discha "Number of full equivalent discharge cycles";
CM_ SG_ 2566852813 Number_of_Full_Equivalent_Charge1 "Number of full equivalent charge-discharge cycles";
CM_ SG_ 2566852813 Temperature_Histogram_0 "Battery system temperature histogram (seconds) of the battery pack.";
CM_ SG_ 2566852813 Temperature_Histogram_1 "Battery system temperature histogram (seconds) of the battery pack.";
CM_ SG_ 2566852813 Temperature_Histogram_2 "Battery system temperature histogram (seconds) of the battery pack.";
CM_ SG_ 2566852813 Temperature_Histogram_3 "Battery system temperature histogram (seconds) of the battery pack.";
CM_ SG_ 2566852813 Temperature_Histogram_4 "Battery system temperature histogram (seconds) of the battery pack.";
CM_ SG_ 2566852813 Temperature_Histogram_5 "Battery system temperature histogram (seconds) of the battery pack.";
CM_ SG_ 2566852813 Temperature_Histogram_6 "Battery system temperature histogram (seconds) of the battery pack.";
CM_ SG_ 2566852813 Temperature_Histogram_7 "Battery system temperature histogram (seconds) of the battery pack.";
CM_ SG_ 2566852813 Temperature_Histogram_8 "Battery system temperature histogram (seconds) of the battery pack.";
CM_ SG_ 2566852813 Temperature_Histogram_9 "Battery system temperature histogram (seconds) of the battery pack.";
CM_ SG_ 2566852813 Temperature_Histogram_10 "Battery system temperature histogram (seconds) of the battery pack.";
CM_ SG_ 2566852813 Temperature_Histogram_11 "Battery system temperature histogram (seconds) of the battery pack.";
CM_ SG_ 2566852813 Temperature_Histogram_12 "Battery system temperature histogram (seconds) of the battery pack.";
CM_ SG_ 2566852813 Temperature_Histogram_13 "Battery system temperature histogram (seconds) of the battery pack.";
CM_ SG_ 2566852813 Temperature_Histogram_14 "Battery system temperature histogram (seconds) of the battery pack.";
CM_ SG_ 2566852813 Temperature_Histogram_15 "Battery system temperature histogram (seconds) of the battery pack.";
CM_ SG_ 2566852813 Temperature_Histogram_16 "Battery system temperature histogram (seconds) of the battery pack.";
CM_ SG_ 2566852813 Temperature_Histogram_17 "Battery system temperature histogram (seconds) of the battery pack.";
CM_ SG_ 2566852813 Temperature_Histogram_18 "Battery system temperature histogram (seconds) of the battery pack.";
CM_ SG_ 2566852813 Temperature_Histogram_19 "Battery system temperature histogram (seconds) of the battery pack.";
CM_ SG_ 2566852813 Temperature_Histogram_20 "Battery system temperature histogram (seconds) of the battery pack.";
CM_ SG_ 2566852813 Temperature_Histogram_21 "Battery system temperature histogram (seconds) of the battery pack.";
CM_ SG_ 2566852813 Temperature_Histogram_22 "Battery system temperature histogram (seconds) of the battery pack.";
CM_ SG_ 2566852813 Temperature_Histogram_23 "Battery system temperature histogram (seconds) of the battery pack.";
CM_ SG_ 2566852813 Time_Spent_in_Extreme_Temperatur0 "Time spent in extreme temperatures above boundary (seconds) of the battery pack.";
CM_ SG_ 2566852813 Time_Spent_in_Extreme_Temperatur1 "Time spent in extreme temperatures below boundary (seconds) of the battery pack.";
CM_ SG_ 2566852813 Number_of_Deep_Discharge_Events "Number of deep discharge events of the battery pack.";
CM_ SG_ 2566852813 Time_Spent_Charging_In_Extreme_T "Time spent charging in extreme temperatures (seconds) of the battery pack.";
CM_ SG_ 2566852813 State_of_Charge "Battery system state of charge";
CM_ SG_ 2566852813 State_of_Charge_Histogram_0 "Battery system state of charge histogram (seconds) of the battery pack.";
CM_ SG_ 2566852813 State_of_Charge_Histogram_1 "Battery system state of charge histogram (seconds) of the battery pack.";
CM_ SG_ 2566852813 State_of_Charge_Histogram_2 "Battery system state of charge histogram (seconds) of the battery pack.";
CM_ SG_ 2566852813 State_of_Charge_Histogram_3 "Battery system state of charge histogram (seconds) of the battery pack.";
CM_ SG_ 2566852813 State_of_Charge_Histogram_4 "Battery system state of charge histogram (seconds) of the battery pack.";
CM_ SG_ 2566852813 State_of_Charge_Histogram_5 "Battery system state of charge histogram (seconds) of the battery pack.";
CM_ SG_ 2566852813 State_of_Charge_Histogram_6 "Battery system state of charge histogram (seconds) of the battery pack.";
CM_ SG_ 2566852813 State_of_Charge_Histogram_7 "Battery system state of charge histogram (seconds) of the battery pack.";
CM_ SG_ 2566852813 State_of_Charge_Histogram_8 "Battery system state of charge histogram (seconds) of the battery pack.";
CM_ SG_ 2566852813 State_of_Charge_Histogram_9 "Battery system state of charge histogram (seconds) of the battery pack.";
CM_ SG_ 2566852813 State_of_Charge_Histogram_10 "Battery system state of charge histogram (seconds) of the battery pack.";
CM_ SG_ 2566852813 State_of_Charge_Histogram_11 "Battery system state of charge histogram (seconds) of the battery pack.";
CM_ SG_ 2566852813 State_of_Charge_Histogram_12 "Battery system state of charge histogram (seconds) of the battery pack.";
CM_ SG_ 2566852813 State_of_Charge_Histogram_13 "Battery system state of charge histogram (seconds) of the battery pack.";
CM_ SG_ 2566852813 State_of_Charge_Histogram_14 "Battery system state of charge histogram (seconds) of the battery pack.";
CM_ SG_ 2566852813 State_of_Charge_Histogram_15 "Battery system state of charge histogram (seconds) of the battery pack.";
CM_ SG_ 2566852813 State_of_Charge_Histogram_16 "Battery system state of charge histogram (seconds) of the battery pack.";
CM_ SG_ 2566852813 State_of_Charge_Histogram_17 "Battery system state of charge histogram (seconds) of the battery pack.";
CM_ SG_ 2566852813 State_of_Charge_Histogram_18 "Battery system state of charge histogram (seconds) of the battery pack.";
CM_ SG_ 2566852813 State_of_Charge_Histogram_19 "Battery system state of charge histogram (seconds) of the battery pack.";
CM_ SG_ 2566852814 Remaining_Capacity "Pack charge capacity";
CM_ SG_ 2566852814 Date_of_Manufacture_0 "Date of manufacture encoded as YYYY-MM";
CM_ SG_ 2566852814 Date_of_Manufacture_1 "Date of manufacture encoded as YYYY-MM";
CM_ SG_ 2566852814 Date_of_Manufacture_2 "Date of manufacture encoded as YYYY-MM";
CM_ SG_ 2566852814 Date_of_Manufacture_3 "Date of manufacture encoded as YYYY-MM";
CM_ SG_ 2566852814 Date_of_Manufacture_4 "Date of manufacture encoded as YYYY-MM";
CM_ SG_ 2566852814 Date_of_Manufacture_5 "Date of manufacture encoded as YYYY-MM";
CM_ SG_ 2566852814 Date_of_Manufacture_6 "Date of manufacture encoded as YYYY-MM";
CM_ SG_ 2566852814 Date_of_Putting_Into_Service_0 "Date of putting into service encoded as YYYY-MM";
CM_ SG_ 2566852814 Date_of_Putting_Into_Service_1 "Date of putting into service encoded as YYYY-MM";
CM_ SG_ 2566852814 Date_of_Putting_Into_Service_2 "Date of putting into service encoded as YYYY-MM";
CM_ SG_ 2566852814 Date_of_Putting_Into_Service_3 "Date of putting into service encoded as YYYY-MM";
CM_ SG_ 2566852814 Date_of_Putting_Into_Service_4 "Date of putting into service encoded as YYYY-MM";
CM_ SG_ 2566852814 Date_of_Putting_Into_Service_5 "Date of putting into service encoded as YYYY-MM";
CM_ SG_ 2566852814 Date_of_Putting_Into_Service_6 "Date of putting into service encoded as YYYY-MM";
CM_ SG_ 2566852814 Charge_Energy_Throughput "Battery system charge energy throughput";
CM_ SG_ 2566852814 Discharge_Energy_Throughput "Battery system discharge energy throughput";
CM_ SG_ 2566852814 Total_Energy_Throughput "Battery system total energy throughput";
CM_ SG_ 2566852814 Charged_Capacity_Throughput "Battery system charged capacity throughput";
CM_ SG_ 2566852814 Discharged_Capacity_Throughput "Battery system discharged capacity throughput";
CM_ SG_ 2566852814 Total_Capacity_Throughput "Battery system total capacity throughput";
CM_ SG_ 2566852814 Number_of_Full_Equivalent_Charge0 "Number of full equivalent charge cycles";
CM_ SG_ 2566852814 Number_of_Full_Equivalent_Discha "Number of full equivalent discharge cycles";
CM_ SG_ 2566852814 Number_of_Full_Equivalent_Charge1 "Number of full equivalent charge-discharge cycles";
CM_ SG_ 2566852814 Temperature_Histogram_0 "Battery system temperature histogram (seconds) of the battery pack.";
CM_ SG_ 2566852814 Temperature_Histogram_1 "Battery system temperature histogram (seconds) of the battery pack.";
CM_ SG_ 2566852814 Temperature_Histogram_2 "Battery system temperature histogram (seconds) of the battery pack.";
CM_ SG_ 2566852814 Temperature_Histogram_3 "Battery system temperature histogram (seconds) of the battery pack.";
CM_ SG_ 2566852814 Temperature_Histogram_4 "Battery system temperature histogram (seconds) of the battery pack.";
CM_ SG_ 2566852814 Temperature_Histogram_5 "Battery system temperature histogram (seconds) of the battery pack.";
CM_ SG_ 2566852814 Temperature_Histogram_6 "Battery system temperature histogram (seconds) of the battery pack.";
CM_ SG_ 2566852814 Temperature_Histogram_7 "Battery system temperature histogram (seconds) of the battery pack.";
CM_ SG_ 2566852814 Temperature_Histogram_8 "Battery system temperature histogram (seconds) of the battery pack.";
CM_ SG_ 2566852814 Temperature_Histogram_9 "Battery system temperature histogram (seconds) of the battery pack.";
CM_ SG_ 2566852814 Temperature_Histogram_10 "Battery system temperature histogram (seconds) of the battery pack.";
CM_ SG_ 2566852814 Temperature_Histogram_11 "Battery system temperature histogram (seconds) of the battery pack.";
CM_ SG_ 2566852814 Temperature_Histogram_12 "Battery system temperature histogram (seconds) of the battery pack.";
CM_ SG_ 2566852814 Temperature_Histogram_13 "Battery system temperature histogram (seconds) of the battery pack.";
CM_ SG_ 2566852814 Temperature_Histogram_14 "Battery system temperature histogram (seconds) of the battery pack.";
CM_ SG_ 2566852814 Temperature_Histogram_15 "Battery system temperature histogram (seconds) of the battery pack.";
CM_ SG_ 2566852814 Temperature_Histogram_16 "Battery system temperature histogram (seconds) of the battery pack.";
CM_ SG_ 2566852814 Temperature_Histogram_17 "Battery system temperature histogram (seconds) of the battery pack.";
CM_ SG_ 2566852814 Temperature_Histogram_18 "Battery system temperature histogram (seconds) of the battery pack.";
CM_ SG_ 2566852814 Temperature_Histogram_19 "Battery system temperature histogram (seconds) of the battery pack.";
CM_ SG_ 2566852814 Temperature_Histogram_20 "Battery system temperature histogram (seconds) of the battery pack.";
CM_ SG_ 2566852814 Temperature_Histogram_21 "Battery system temperature histogram (seconds) of the battery pack.";
CM_ SG_ 2566852814 Temperature_Histogram_22 "Battery system temperature histogram (seconds) of the battery pack.";
CM_ SG_ 2566852814 Temperature_Histogram_23 "Battery system temperature histogram (seconds) of the battery pack.";
CM_ SG_ 2566852814 Time_Spent_in_Extreme_Temperatur0 "Time spent in extreme temperatures above boundary (seconds) of the battery pack.";
CM_ SG_ 2566852814 Time_Spent_in_Extreme_Temperatur1 "Time spent in extreme temperatures below boundary (seconds) of the battery pack.";
CM_ SG_ 2566852814 Number_of_Deep_Discharge_Events "Number of deep discharge events of the battery pack.";
CM_ SG_ 2566852814 Time_Spent_Charging_In_Extreme_T "Time spent charging in extreme temperatures (seconds) of the battery pack.";
CM_ SG_ 2566852814 State_of_Charge "Battery system state of charge";
CM_ SG_ 2566852814 State_of_Charge_Histogram_0 "Battery system state of charge histogram (seconds) of the battery pack.";
CM_ SG_ 2566852814 State_of_Charge_Histogram_1 "Battery system state of charge histogram (seconds) of the battery pack.";
CM_ SG_ 2566852814 State_of_Charge_Histogram_2 "Battery system state of charge histogram (seconds) of the battery pack.";
CM_ SG_ 2566852814 State_of_Charge_Histogram_3 "Battery system state of charge histogram (seconds) of the battery pack.";
CM_ SG_ 2566852814 State_of_Charge_Histogram_4 "Battery system state of charge histogram (seconds) of the battery pack.";
CM_ SG_ 2566852814 State_of_Charge_Histogram_5 "Battery system state of charge histogram (seconds) of the battery pack.";
CM_ SG_ 2566852814 State_of_Charge_Histogram_6 "Battery system state of charge histogram (seconds) of the battery pack.";
CM_ SG_ 2566852814 State_of_Charge_Histogram_7 "Battery system state of charge histogram (seconds) of the battery pack.";
CM_ SG_ 2566852814 State_of_Charge_Histogram_8 "Battery system state of charge histogram (seconds) of the battery pack.";
CM_ SG_ 2566852814 State_of_Charge_Histogram_9 "Battery system state of charge histogram (seconds) of the battery pack.";
CM_ SG_ 2566852814 State_of_Charge_Histogram_10 "Battery system state of charge histogram (seconds) of the battery pack.";
CM_ SG_ 2566852814 State_of_Charge_Histogram_11 "Battery system state of charge histogram (seconds) of the battery pack.";
CM_ SG_ 2566852814 State_of_Charge_Histogram_12 "Battery system state of charge histogram (seconds) of the battery pack.";
CM_ SG_ 2566852814 State_of_Charge_Histogram_13 "Battery system state of charge histogram (seconds) of the battery pack.";
CM_ SG_ 2566852814 State_of_Charge_Histogram_14 "Battery system state of charge histogram (seconds) of the battery pack.";
CM_ SG_ 2566852814 State_of_Charge_Histogram_15 "Battery system state of charge histogram (seconds) of the battery pack.";
CM_ SG_ 2566852814 State_of_Charge_Histogram_16 "Battery system state of charge histogram (seconds) of the battery pack.";
CM_ SG_ 2566852814 State_of_Charge_Histogram_17 "Battery system state of charge histogram (seconds) of the battery pack.";
CM_ SG_ 2566852814 State_of_Charge_Histogram_18 "Battery system state of charge histogram (seconds) of the battery pack.";
CM_ SG_ 2566852814 State_of_Charge_Histogram_19 "Battery system state of charge histogram (seconds) of the battery pack.";
CM_ SG_ 2566852815 Remaining_Capacity "Pack charge capacity";
CM_ SG_ 2566852815 Date_of_Manufacture_0 "Date of manufacture encoded as YYYY-MM";
CM_ SG_ 2566852815 Date_of_Manufacture_1 "Date of manufacture encoded as YYYY-MM";
CM_ SG_ 2566852815 Date_of_Manufacture_2 "Date of manufacture encoded as YYYY-MM";
CM_ SG_ 2566852815 Date_of_Manufacture_3 "Date of manufacture encoded as YYYY-MM";
CM_ SG_ 2566852815 Date_of_Manufacture_4 "Date of manufacture encoded as YYYY-MM";
CM_ SG_ 2566852815 Date_of_Manufacture_5 "Date of manufacture encoded as YYYY-MM";
CM_ SG_ 2566852815 Date_of_Manufacture_6 "Date of manufacture encoded as YYYY-MM";
CM_ SG_ 2566852815 Date_of_Putting_Into_Service_0 "Date of putting into service encoded as YYYY-MM";
CM_ SG_ 2566852815 Date_of_Putting_Into_Service_1 "Date of putting into service encoded as YYYY-MM";
CM_ SG_ 2566852815 Date_of_Putting_Into_Service_2 "Date of putting into service encoded as YYYY-MM";
CM_ SG_ 2566852815 Date_of_Putting_Into_Service_3 "Date of putting into service encoded as YYYY-MM";
CM_ SG_ 2566852815 Date_of_Putting_Into_Service_4 "Date of putting into service encoded as YYYY-MM";
CM_ SG_ 2566852815 Date_of_Putting_Into_Service_5 "Date of putting into service encoded as YYYY-MM";
CM_ SG_ 2566852815 Date_of_Putting_Into_Service_6 "Date of putting into service encoded as YYYY-MM";
CM_ SG_ 2566852815 Charge_Energy_Throughput "Battery system charge energy throughput";
CM_ SG_ 2566852815 Discharge_Energy_Throughput "Battery system discharge energy throughput";
CM_ SG_ 2566852815 Total_Energy_Throughput "Battery system total energy throughput";
CM_ SG_ 2566852815 Charged_Capacity_Throughput "Battery system charged capacity throughput";
CM_ SG_ 2566852815 Discharged_Capacity_Throughput "Battery system discharged capacity throughput";
CM_ SG_ 2566852815 Total_Capacity_Throughput "Battery system total capacity throughput";
CM_ SG_ 2566852815 Number_of_Full_Equivalent_Charge0 "Number of full equivalent charge cycles";
CM_ SG_ 2566852815 Number_of_Full_Equivalent_Discha "Number of full equivalent discharge cycles";
CM_ SG_ 2566852815 Number_of_Full_Equivalent_Charge1 "Number of full equivalent charge-discharge cycles";
CM_ SG_ 2566852815 Temperature_Histogram_0 "Battery system temperature histogram (seconds) of the battery pack.";
CM_ SG_ 2566852815 Temperature_Histogram_1 "Battery system temperature histogram (seconds) of the battery pack.";
CM_ SG_ 2566852815 Temperature_Histogram_2 "Battery system temperature histogram (seconds) of the battery pack.";
CM_ SG_ 2566852815 Temperature_Histogram_3 "Battery system temperature histogram (seconds) of the battery pack.";
CM_ SG_ 2566852815 Temperature_Histogram_4 "Battery system temperature histogram (seconds) of the battery pack.";
CM_ SG_ 2566852815 Temperature_Histogram_5 "Battery system temperature histogram (seconds) of the battery pack.";
CM_ SG_ 2566852815 Temperature_Histogram_6 "Battery system temperature histogram (seconds) of the battery pack.";
CM_ SG_ 2566852815 Temperature_Histogram_7 "Battery system temperature histogram (seconds) of the battery pack.";
CM_ SG_ 2566852815 Temperature_Histogram_8 "Battery system temperature histogram (seconds) of the battery pack.";
CM_ SG_ 2566852815 Temperature_Histogram_9 "Battery system temperature histogram (seconds) of the battery pack.";
CM_ SG_ 2566852815 Temperature_Histogram_10 "Battery system temperature histogram (seconds) of the battery pack.";
CM_ SG_ 2566852815 Temperature_Histogram_11 "Battery system temperature histogram (seconds) of the battery pack.";
CM_ SG_ 2566852815 Temperature_Histogram_12 "Battery system temperature histogram (seconds) of the battery pack.";
CM_ SG_ 2566852815 Temperature_Histogram_13 "Battery system temperature histogram (seconds) of the battery pack.";
CM_ SG_ 2566852815 Temperature_Histogram_14 "Battery system temperature histogram (seconds) of the battery pack.";
CM_ SG_ 2566852815 Temperature_Histogram_15 "Battery system temperature histogram (seconds) of the battery pack.";
CM_ SG_ 2566852815 Temperature_Histogram_16 "Battery system temperature histogram (seconds) of the battery pack.";
CM_ SG_ 2566852815 Temperature_Histogram_17 "Battery system temperature histogram (seconds) of the battery pack.";
CM_ SG_ 2566852815 Temperature_Histogram_18 "Battery system temperature histogram (seconds) of the battery pack.";
CM_ SG_ 2566852815 Temperature_Histogram_19 "Battery system temperature histogram (seconds) of the battery pack.";
CM_ SG_ 2566852815 Temperature_Histogram_20 "Battery system temperature histogram (seconds) of the battery pack.";
CM_ SG_ 2566852815 Temperature_Histogram_21 "Battery system temperature histogram (seconds) of the battery pack.";
CM_ SG_ 2566852815 Temperature_Histogram_22 "Battery system temperature histogram (seconds) of the battery pack.";
CM_ SG_ 2566852815 Temperature_Histogram_23 "Battery system temperature histogram (seconds) of the battery pack.";
CM_ SG_ 2566852815 Time_Spent_in_Extreme_Temperatur0 "Time spent in extreme temperatures above boundary (seconds) of the battery pack.";
CM_ SG_ 2566852815 Time_Spent_in_Extreme_Temperatur1 "Time spent in extreme temperatures below boundary (seconds) of the battery pack.";
CM_ SG_ 2566852815 Number_of_Deep_Discharge_Events "Number of deep discharge events of the battery pack.";
CM_ SG_ 2566852815 Time_Spent_Charging_In_Extreme_T "Time spent charging in extreme temperatures (seconds) of the battery pack.";
CM_ SG_ 2566852815 State_of_Charge "Battery system state of charge";
CM_ SG_ 2566852815 State_of_Charge_Histogram_0 "Battery system state of charge histogram (seconds) of the battery pack.";
CM_ SG_ 2566852815 State_of_Charge_Histogram_1 "Battery system state of charge histogram (seconds) of the battery pack.";
CM_ SG_ 2566852815 State_of_Charge_Histogram_2 "Battery system state of charge histogram (seconds) of the battery pack.";
CM_ SG_ 2566852815 State_of_Charge_Histogram_3 "Battery system state of charge histogram (seconds) of the battery pack.";
CM_ SG_ 2566852815 State_of_Charge_Histogram_4 "Battery system state of charge histogram (seconds) of the battery pack.";
CM_ SG_ 2566852815 State_of_Charge_Histogram_5 "Battery system state of charge histogram (seconds) of the battery pack.";
CM_ SG_ 2566852815 State_of_Charge_Histogram_6 "Battery system state of charge histogram (seconds) of the battery pack.";
CM_ SG_ 2566852815 State_of_Charge_Histogram_7 "Battery system state of charge histogram (seconds) of the battery pack.";
CM_ SG_ 2566852815 State_of_Charge_Histogram_8 "Battery system state of charge histogram (seconds) of the battery pack.";
CM_ SG_ 2566852815 State_of_Charge_Histogram_9 "Battery system state of charge histogram (seconds) of the battery pack.";
CM_ SG_ 2566852815 State_of_Charge_Histogram_10 "Battery system state of charge histogram (seconds) of the battery pack.";
CM_ SG_ 2566852815 State_of_Charge_Histogram_11 "Battery system state of charge histogram (seconds) of the battery pack.";
CM_ SG_ 2566852815 State_of_Charge_Histogram_12 "Battery system state of charge histogram (seconds) of the battery pack.";
CM_ SG_ 2566852815 State_of_Charge_Histogram_13 "Battery system state of charge histogram (seconds) of the battery pack.";
CM_ SG_ 2566852815 State_of_Charge_Histogram_14 "Battery system state of charge histogram (seconds) of the battery pack.";
CM_ SG_ 2566852815 State_of_Charge_Histogram_15 "Battery system state of charge histogram (seconds) of the battery pack.";
CM_ SG_ 2566852815 State_of_Charge_Histogram_16 "Battery system state of charge histogram (seconds) of the battery pack.";
CM_ SG_ 2566852815 State_of_Charge_Histogram_17 "Battery system state of charge histogram (seconds) of the battery pack.";
CM_ SG_ 2566852815 State_of_Charge_Histogram_18 "Battery system state of charge histogram (seconds) of the battery pack.";
CM_ SG_ 2566852815 State_of_Charge_Histogram_19 "Battery system state of charge histogram (seconds) of the battery pack.";
CM_ SG_ 2566852816 Remaining_Capacity "Pack charge capacity";
CM_ SG_ 2566852816 Date_of_Manufacture_0 "Date of manufacture encoded as YYYY-MM";
CM_ SG_ 2566852816 Date_of_Manufacture_1 "Date of manufacture encoded as YYYY-MM";
CM_ SG_ 2566852816 Date_of_Manufacture_2 "Date of manufacture encoded as YYYY-MM";
CM_ SG_ 2566852816 Date_of_Manufacture_3 "Date of manufacture encoded as YYYY-MM";
CM_ SG_ 2566852816 Date_of_Manufacture_4 "Date of manufacture encoded as YYYY-MM";
CM_ SG_ 2566852816 Date_of_Manufacture_5 "Date of manufacture encoded as YYYY-MM";
CM_ SG_ 2566852816 Date_of_Manufacture_6 "Date of manufacture encoded as YYYY-MM";
CM_ SG_ 2566852816 Date_of_Putting_Into_Service_0 "Date of putting into service encoded as YYYY-MM";
CM_ SG_ 2566852816 Date_of_Putting_Into_Service_1 "Date of putting into service encoded as YYYY-MM";
CM_ SG_ 2566852816 Date_of_Putting_Into_Service_2 "Date of putting into service encoded as YYYY-MM";
CM_ SG_ 2566852816 Date_of_Putting_Into_Service_3 "Date of putting into service encoded as YYYY-MM";
CM_ SG_ 2566852816 Date_of_Putting_Into_Service_4 "Date of putting into service encoded as YYYY-MM";
CM_ SG_ 2566852816 Date_of_Putting_Into_Service_5 "Date of putting into service encoded as YYYY-MM";
CM_ SG_ 2566852816 Date_of_Putting_Into_Service_6 "Date of putting into service encoded as YYYY-MM";
CM_ SG_ 2566852816 Charge_Energy_Throughput "Battery system charge energy throughput";
CM_ SG_ 2566852816 Discharge_Energy_Throughput "Battery system discharge energy throughput";
CM_ SG_ 2566852816 Total_Energy_Throughput "Battery system total energy throughput";
CM_ SG_ 2566852816 Charged_Capacity_Throughput "Battery system charged capacity throughput";
CM_ SG_ 2566852816 Discharged_Capacity_Throughput "Battery system discharged capacity throughput";
CM_ SG_ 2566852816 Total_Capacity_Throughput "Battery system total capacity throughput";
CM_ SG_ 2566852816 Number_of_Full_Equivalent_Charge0 "Number of full equivalent charge cycles";
CM_ SG_ 2566852816 Number_of_Full_Equivalent_Discha "Number of full equivalent discharge cycles";
CM_ SG_ 2566852816 Number_of_Full_Equivalent_Charge1 "Number of full equivalent charge-discharge cycles";
CM_ SG_ 2566852816 Temperature_Histogram_0 "Battery system temperature histogram (seconds) of the battery pack.";
CM_ SG_ 2566852816 Temperature_Histogram_1 "Battery system temperature histogram (seconds) of the battery pack.";
CM_ SG_ 2566852816 Temperature_Histogram_2 "Battery system temperature histogram (seconds) of the battery pack.";
CM_ SG_ 2566852816 Temperature_Histogram_3 "Battery system temperature histogram (seconds) of the battery pack.";
CM_ SG_ 2566852816 Temperature_Histogram_4 "Battery system temperature histogram (seconds) of the battery pack.";
CM_ SG_ 2566852816 Temperature_Histogram_5 "Battery system temperature histogram (seconds) of the battery pack.";
CM_ SG_ 2566852816 Temperature_Histogram_6 "Battery system temperature histogram (seconds) of the battery pack.";
CM_ SG_ 2566852816 Temperature_Histogram_7 "Battery system temperature histogram (seconds) of the battery pack.";
CM_ SG_ 2566852816 Temperature_Histogram_8 "Battery system temperature histogram (seconds) of the battery pack.";
CM_ SG_ 2566852816 Temperature_Histogram_9 "Battery system temperature histogram (seconds) of the battery pack.";
CM_ SG_ 2566852816 Temperature_Histogram_10 "Battery system temperature histogram (seconds) of the battery pack.";
CM_ SG_ 2566852816 Temperature_Histogram_11 "Battery system temperature histogram (seconds) of the battery pack.";
CM_ SG_ 2566852816 Temperature_Histogram_12 "Battery system temperature histogram (seconds) of the battery pack.";
CM_ SG_ 2566852816 Temperature_Histogram_13 "Battery system temperature histogram (seconds) of the battery pack.";
CM_ SG_ 2566852816 Temperature_Histogram_14 "Battery system temperature histogram (seconds) of the battery pack.";
CM_ SG_ 2566852816 Temperature_Histogram_15 "Battery system temperature histogram (seconds) of the battery pack.";
CM_ SG_ 2566852816 Temperature_Histogram_16 "Battery system temperature histogram (seconds) of the battery pack.";
CM_ SG_ 2566852816 Temperature_Histogram_17 "Battery system temperature histogram (seconds) of the battery pack.";
CM_ SG_ 2566852816 Temperature_Histogram_18 "Battery system temperature histogram (seconds) of the battery pack.";
CM_ SG_ 2566852816 Temperature_Histogram_19 "Battery system temperature histogram (seconds) of the battery pack.";
CM_ SG_ 2566852816 Temperature_Histogram_20 "Battery system temperature histogram (seconds) of the battery pack.";
CM_ SG_ 2566852816 Temperature_Histogram_21 "Battery system temperature histogram (seconds) of the battery pack.";
CM_ SG_ 2566852816 Temperature_Histogram_22 "Battery system temperature histogram (seconds) of the battery pack.";
CM_ SG_ 2566852816 Temperature_Histogram_23 "Battery system temperature histogram (seconds) of the battery pack.";
CM_ SG_ 2566852816 Time_Spent_in_Extreme_Temperatur0 "Time spent in extreme temperatures above boundary (seconds) of the battery pack.";
CM_ SG_ 2566852816 Time_Spent_in_Extreme_Temperatur1 "Time spent in extreme temperatures below boundary (seconds) of the battery pack.";
CM_ SG_ 2566852816 Number_of_Deep_Discharge_Events "Number of deep discharge events of the battery pack.";
CM_ SG_ 2566852816 Time_Spent_Charging_In_Extreme_T "Time spent charging in extreme temperatures (seconds) of the battery pack.";
CM_ SG_ 2566852816 State_of_Charge "Battery system state of charge";
CM_ SG_ 2566852816 State_of_Charge_Histogram_0 "Battery system state of charge histogram (seconds) of the battery pack.";
CM_ SG_ 2566852816 State_of_Charge_Histogram_1 "Battery system state of charge histogram (seconds) of the battery pack.";
CM_ SG_ 2566852816 State_of_Charge_Histogram_2 "Battery system state of charge histogram (seconds) of the battery pack.";
CM_ SG_ 2566852816 State_of_Charge_Histogram_3 "Battery system state of charge histogram (seconds) of the battery pack.";
CM_ SG_ 2566852816 State_of_Charge_Histogram_4 "Battery system state of charge histogram (seconds) of the battery pack.";
CM_ SG_ 2566852816 State_of_Charge_Histogram_5 "Battery system state of charge histogram (seconds) of the battery pack.";
CM_ SG_ 2566852816 State_of_Charge_Histogram_6 "Battery system state of charge histogram (seconds) of the battery pack.";
CM_ SG_ 2566852816 State_of_Charge_Histogram_7 "Battery system state of charge histogram (seconds) of the battery pack.";
CM_ SG_ 2566852816 State_of_Charge_Histogram_8 "Battery system state of charge histogram (seconds) of the battery pack.";
CM_ SG_ 2566852816 State_of_Charge_Histogram_9 "Battery system state of charge histogram (seconds) of the battery pack.";
CM_ SG_ 2566852816 State_of_Charge_Histogram_10 "Battery system state of charge histogram (seconds) of the battery pack.";
CM_ SG_ 2566852816 State_of_Charge_Histogram_11 "Battery system state of charge histogram (seconds) of the battery pack.";
CM_ SG_ 2566852816 State_of_Charge_Histogram_12 "Battery system state of charge histogram (seconds) of the battery pack.";
CM_ SG_ 2566852816 State_of_Charge_Histogram_13 "Battery system state of charge histogram (seconds) of the battery pack.";
CM_ SG_ 2566852816 State_of_Charge_Histogram_14 "Battery system state of charge histogram (seconds) of the battery pack.";
CM_ SG_ 2566852816 State_of_Charge_Histogram_15 "Battery system state of charge histogram (seconds) of the battery pack.";
CM_ SG_ 2566852816 State_of_Charge_Histogram_16 "Battery system state of charge histogram (seconds) of the battery pack.";
CM_ SG_ 2566852816 State_of_Charge_Histogram_17 "Battery system state of charge histogram (seconds) of the battery pack.";
CM_ SG_ 2566852816 State_of_Charge_Histogram_18 "Battery system state of charge histogram (seconds) of the battery pack.";
CM_ SG_ 2566852816 State_of_Charge_Histogram_19 "Battery system state of charge histogram (seconds) of the battery pack.";

BA_DEF_ BO_ "GenMsgCycleTime" INT 0 65535;
BA_DEF_ BO_ "VFrameFormat" ENUM  "StandardCAN","ExtendedCAN","reserved","J1939PG";
BA_DEF_ SG_ "GenSigStartValue" FLOAT 0 100000000000;
BA_DEF_  "ProtocolType" STRING;

BA_ "ProtocolType"   "J1939";

BA_ "GenMsgCycleTime" BO_ 2566834889 1000;
BA_ "VFrameFormat" BO_ 2566834889 3;
BA_ "GenMsgCycleTime" BO_ 2350631173 20;
BA_ "VFrameFormat" BO_ 2350631173 3;
BA_ "GenMsgCycleTime" BO_ 2364575945 20;
BA_ "VFrameFormat" BO_ 2364575945 3;
BA_ "GenMsgCycleTime" BO_ 2364607689 100;
BA_ "VFrameFormat" BO_ 2364607689 3;
BA_ "GenMsgCycleTime" BO_ 2365203657 100;
BA_ "VFrameFormat" BO_ 2365203657 3;
BA_ "GenMsgCycleTime" BO_ 2364576201 20;
BA_ "VFrameFormat" BO_ 2364576201 3;
BA_ "GenMsgCycleTime" BO_ 2364576457 20;
BA_ "VFrameFormat" BO_ 2364576457 3;
BA_ "GenMsgCycleTime" BO_ 2364576713 100;
BA_ "VFrameFormat" BO_ 2364576713 3;
BA_ "GenMsgCycleTime" BO_ 2364576969 20;
BA_ "VFrameFormat" BO_ 2364576969 3;
BA_ "GenMsgCycleTime" BO_ 2364577225 100;
BA_ "VFrameFormat" BO_ 2364577225 3;
BA_ "GenMsgCycleTime" BO_ 2364607177 100;
BA_ "VFrameFormat" BO_ 2364607177 3;
BA_ "GenMsgCycleTime" BO_ 2364607433 100;
BA_ "VFrameFormat" BO_ 2364607433 3;
BA_ "GenMsgCycleTime" BO_ 2633785033 1000;
BA_ "VFrameFormat" BO_ 2633785033 3;
BA_ "GenMsgCycleTime" BO_ 2364577481 100;
BA_ "VFrameFormat" BO_ 2364577481 3;
BA_ "GenMsgCycleTime" BO_ 2365522181 100;
BA_ "VFrameFormat" BO_ 2365522181 3;
BA_ "GenMsgCycleTime" BO_ 2365522437 1000;
BA_ "VFrameFormat" BO_ 2365522437 3;
BA_ "GenMsgCycleTime" BO_ 2365523145 1000;
BA_ "VFrameFormat" BO_ 2365523145 3;
BA_ "GenMsgCycleTime" BO_ 2365523401 1000;
BA_ "VFrameFormat" BO_ 2365523401 3;
BA_ "VFrameFormat" BO_ 2566852809 3;
BA_ "GenMsgCycleTime" BO_ 2365526473 20;
BA_ "VFrameFormat" BO_ 2365526473 3;
BA_ "GenMsgCycleTime" BO_ 2365526729 20;
BA_ "VFrameFormat" BO_ 2365526729 3;
BA_ "GenMsgCycleTime" BO_ 2365526985 20;
BA_ "VFrameFormat" BO_ 2365526985 3;
BA_ "VFrameFormat" BO_ 2566838985 3;
BA_ "VFrameFormat" BO_ 2566768073 3;
BA_ "VFrameFormat" BO_ 2566843337 3;
BA_ "GenMsgCycleTime" BO_ 2566834890 1000;
BA_ "VFrameFormat" BO_ 2566834890 3;
BA_ "GenMsgCycleTime" BO_ 2566834891 1000;
BA_ "VFrameFormat" BO_ 2566834891 3;
BA_ "GenMsgCycleTime" BO_ 2566834892 1000;
BA_ "VFrameFormat" BO_ 2566834892 3;
BA_ "GenMsgCycleTime" BO_ 2566834893 1000;
BA_ "VFrameFormat" BO_ 2566834893 3;
BA_ "GenMsgCycleTime" BO_ 2566834894 1000;
BA_ "VFrameFormat" BO_ 2566834894 3;
BA_ "GenMsgCycleTime" BO_ 2566834895 1000;
BA_ "VFrameFormat" BO_ 2566834895 3;
BA_ "GenMsgCycleTime" BO_ 2566834896 1000;
BA_ "VFrameFormat" BO_ 2566834896 3;
BA_ "GenMsgCycleTime" BO_ 2566834897 1000;
BA_ "VFrameFormat" BO_ 2566834897 3;
BA_ "GenMsgCycleTime" BO_ 2566834898 1000;
BA_ "VFrameFormat" BO_ 2566834898 3;
BA_ "GenMsgCycleTime" BO_ 2566834899 1000;
BA_ "VFrameFormat" BO_ 2566834899 3;
BA_ "GenMsgCycleTime" BO_ 2566834900 1000;
BA_ "VFrameFormat" BO_ 2566834900 3;
BA_ "GenMsgCycleTime" BO_ 2566834901 1000;
BA_ "VFrameFormat" BO_ 2566834901 3;
BA_ "GenMsgCycleTime" BO_ 2566834902 1000;
BA_ "VFrameFormat" BO_ 2566834902 3;
BA_ "GenMsgCycleTime" BO_ 2566834903 1000;
BA_ "VFrameFormat" BO_ 2566834903 3;
BA_ "GenMsgCycleTime" BO_ 2566834904 1000;
BA_ "VFrameFormat" BO_ 2566834904 3;
BA_ "VFrameFormat" BO_ 2566852810 3;
BA_ "VFrameFormat" BO_ 2566852811 3;
BA_ "VFrameFormat" BO_ 2566852812 3;
BA_ "VFrameFormat" BO_ 2566852813 3;
BA_ "VFrameFormat" BO_ 2566852814 3;
BA_ "VFrameFormat" BO_ 2566852815 3;
BA_ "VFrameFormat" BO_ 2566852816 3;

BA_ "GenSigStartValue" SG_ 2364575945 HVESS_Current 32000;
BA_ "GenSigStartValue" SG_ 2364576457 HVESS_Highest_Cell_Temperature 8736;
BA_ "GenSigStartValue" SG_ 2364576457 HVESS_Lowest_Cell_Temperature 8736;
BA_ "GenSigStartValue" SG_ 2365526729 HVESS_Available_Discharge_Curren 32000;
BA_ "GenSigStartValue" SG_ 2365526729 HVESS_Available_Charge_Current 32000;
BA_ "GenSigStartValue" SG_ 2365526729 HVESS_Available_Pulse_Discharge_ 32000;
BA_ "GenSigStartValue" SG_ 2365526729 HVESS_Available_Pulse_Charge_Cur 32000;
BA_ "GenSigStartValue" SG_ 2365526985 HVESS_Current_Extended_Range 32000;

VAL_ 2350631173 HVESS_High_Voltage_Bus_Connect_C 0 "Open Contactor; Disconnect HVES " 1 "Close Contactor; Connect HVES to" 2 "Emergency contactor closure requ" 3 "Don't care/Take no action (Treat";
VAL_ 2350631173 HVESS_Charging_Mode 0 "Intent to discharge" 1 "Intent to charge" 2 "Intent to fast charge" 3 "Intent to charge for longevity";
VAL_ 2364575945 HVESS_Available_Discharge_Power 65024 "Error" 65280 "Not Available";
VAL_ 2364575945 HVESS_Available_Charge_Power 65024 "Error" 65280 "Not Available";
VAL_ 2364575945 HVESS_Voltage_Level 65024 "Error" 65280 "Not Available";
VAL_ 2364575945 HVESS_Current 65024 "Error" 65280 "Not Available";
VAL_ 2364607689 HVESS_Highest_Cell_State_of_Char 254 "Error" 255 "Not Available";
VAL_ 2364607689 HVESS_Lowest_Cell_State_of_Charg 254 "Error" 255 "Not Available";
VAL_ 2364607689 HVESS_High_Voltage_Bus_Passive_I 65024 "Error" 65280 "Not Available";
VAL_ 2365203657 HVESS_Estimated_Charge_Time_Rema 65024 "Error" 65280 "Not Available";
VAL_ 2364576201 HVESS_Fast_Update_State_of_Charg 65024 "Error" 65280 "Not Available";
VAL_ 2364576201 HVESS_Highest_Cell_Voltage 65024 "Error" 65280 "Not Available";
VAL_ 2364576201 HVESS_Lowest_Cell_Voltage 65024 "Error" 65280 "Not Available";
VAL_ 2364576457 HVESS_Highest_Cell_Temperature 65024 "Error" 65280 "Not Available";
VAL_ 2364576457 HVESS_Lowest_Cell_Temperature 65024 "Error" 65280 "Not Available";
VAL_ 2364576713 HVESS_Discharge_Capacity 65024 "Error" 65280 "Not Available";
VAL_ 2364576713 HVESS_Charge_Capacity 65024 "Error" 65280 "Not Available";
VAL_ 2364576969 HVESS_Minimum_Cell_State_of_Char 65024 "Error" 65280 "Not Available";
VAL_ 2364576969 HVESS_Maximum_Cell_State_of_Char 65024 "Error" 65280 "Not Available";
VAL_ 2364577225 HVESS_Bus_Voltage 65024 "Error" 65280 "Not Available";
VAL_ 2364607177 HVESS_Highest_Cell_Voltage_Pack_ 254 "Error" 255 "Not Available";
VAL_ 2364607177 HVESS_Lowest_Cell_Voltage_Pack_N 254 "Error" 255 "Not Available";
VAL_ 2364607433 HVESS_Highest_Cell_Temperature_P 254 "Error" 255 "Not Available";
VAL_ 2364607433 HVESS_Lowest_Cell_Temperature_Pa 254 "Error" 255 "Not Available";
VAL_ 2633785033 HVESS_State_of_Health 254 "Error" 255 "Not Available";
VAL_ 2364577481 HVESS_High_Voltage_Bus_Disconnec 0 "Disconnect not pending" 1 "Disconnect imminent due to batte" 2 "Disconnect imminent due to batte" 3 "Disconnect imminent due to modul" 4 "Disconnect imminent due to modul" 5 "Disconnect imminent due to cell " 6 "Disconnect imminent due to cell " 7 "Disconnect imminent due to batte" 8 "Reserved" 9 "Reserved" 10 "Reserved" 11 "Reserved" 12 "Reserved" 13 "Disconnect imminent - no reason " 14 "Error" 15 "Not Available";
VAL_ 2364577481 HVESS_High_Voltage_Bus_Connectio 0 "Disconnected" 1 "Connected" 2 "Connection in Process" 3 "Disconnection in Process" 4 "Disconnected; Precharge Failed" 5 "Reserved" 6 "Reserved" 7 "Reserved" 8 "Reserved" 9 "Reserved" 10 "Reserved" 11 "Reserved" 12 "Reserved" 13 "Reserved" 14 "Error" 15 "Not Available";
VAL_ 2364577481 HVESS_Operational_Status 0 "Initialization in process" 1 "Awaiting Operation Consent" 2 "Operational" 3 "Normal Power-Down in Process" 4 "Emergency Power-Down In Process" 5 "Disabled by external command" 6 "Disabled by internal decision of" 7 "Reserved" 8 "Reserved" 9 "Reserved" 10 "Reserved" 11 "Reserved" 12 "Reserved" 13 "Reserved" 14 "Error" 15 "Not Available";
VAL_ 2365522181 External_Clear_DMs_Command 0 "Clear DMs not requested" 1 "Clear DMs requested" 2 "Reserved" 3 "Don't care/Take no action (Treat";
VAL_ 2365522181 Pack01_Disable_Command 0 "Disable core not requested" 1 "Disable core requested" 2 "Reserved" 3 "Don't care/Take no action (Treat";
VAL_ 2365522181 Pack02_Disable_Command 0 "Disable core not requested" 1 "Disable core requested" 2 "Reserved" 3 "Don't care/Take no action (Treat";
VAL_ 2365522181 Pack03_Disable_Command 0 "Disable core not requested" 1 "Disable core requested" 2 "Reserved" 3 "Don't care/Take no action (Treat";
VAL_ 2365522181 Pack04_Disable_Command 0 "Disable core not requested" 1 "Disable core requested" 2 "Reserved" 3 "Don't care/Take no action (Treat";
VAL_ 2365522181 Pack05_Disable_Command 0 "Disable core not requested" 1 "Disable core requested" 2 "Reserved" 3 "Don't care/Take no action (Treat";
VAL_ 2365522181 Pack06_Disable_Command 0 "Disable core not requested" 1 "Disable core requested" 2 "Reserved" 3 "Don't care/Take no action (Treat";
VAL_ 2365522181 Pack07_Disable_Command 0 "Disable core not requested" 1 "Disable core requested" 2 "Reserved" 3 "Don't care/Take no action (Treat";
VAL_ 2365522181 Pack08_Disable_Command 0 "Disable core not requested" 1 "Disable core requested" 2 "Reserved" 3 "Don't care/Take no action (Treat";
VAL_ 2365522181 Pack09_Disable_Command 0 "Disable core not requested" 1 "Disable core requested" 2 "Reserved" 3 "Don't care/Take no action (Treat";
VAL_ 2365522181 Pack10_Disable_Command 0 "Disable core not requested" 1 "Disable core requested" 2 "Reserved" 3 "Don't care/Take no action (Treat";
VAL_ 2365522181 Pack11_Disable_Command 0 "Disable core not requested" 1 "Disable core requested" 2 "Reserved" 3 "Don't care/Take no action (Treat";
VAL_ 2365522181 Pack12_Disable_Command 0 "Disable core not requested" 1 "Disable core requested" 2 "Reserved" 3 "Don't care/Take no action (Treat";
VAL_ 2365522181 Pack13_Disable_Command 0 "Disable core not requested" 1 "Disable core requested" 2 "Reserved" 3 "Don't care/Take no action (Treat";
VAL_ 2365522181 Pack14_Disable_Command 0 "Disable core not requested" 1 "Disable core requested" 2 "Reserved" 3 "Don't care/Take no action (Treat";
VAL_ 2365522181 Pack15_Disable_Command 0 "Disable core not requested" 1 "Disable core requested" 2 "Reserved" 3 "Don't care/Take no action (Treat";
VAL_ 2365522181 Pack16_Disable_Command 0 "Disable core not requested" 1 "Disable core requested" 2 "Reserved" 3 "Don't care/Take no action (Treat";
VAL_ 2365522437 Number_Packs_Configured 254 "Error" 255 "Not Available";
VAL_ 2365523145 Number_Packs_Operational 254 "Error" 255 "Not Available";
VAL_ 2365523145 Number_Packs_Disabled_Internal 254 "Error" 255 "Not Available";
VAL_ 2365523145 Number_Packs_Connected 254 "Error" 255 "Not Available";
VAL_ 2365526985 HVESS_Current_Extended_Range 65024 "Error" 65280 "Not Available";
